AUTOSAR XML (schema 4-2-2)
package /STELLANTIS/EPT/ASWCs
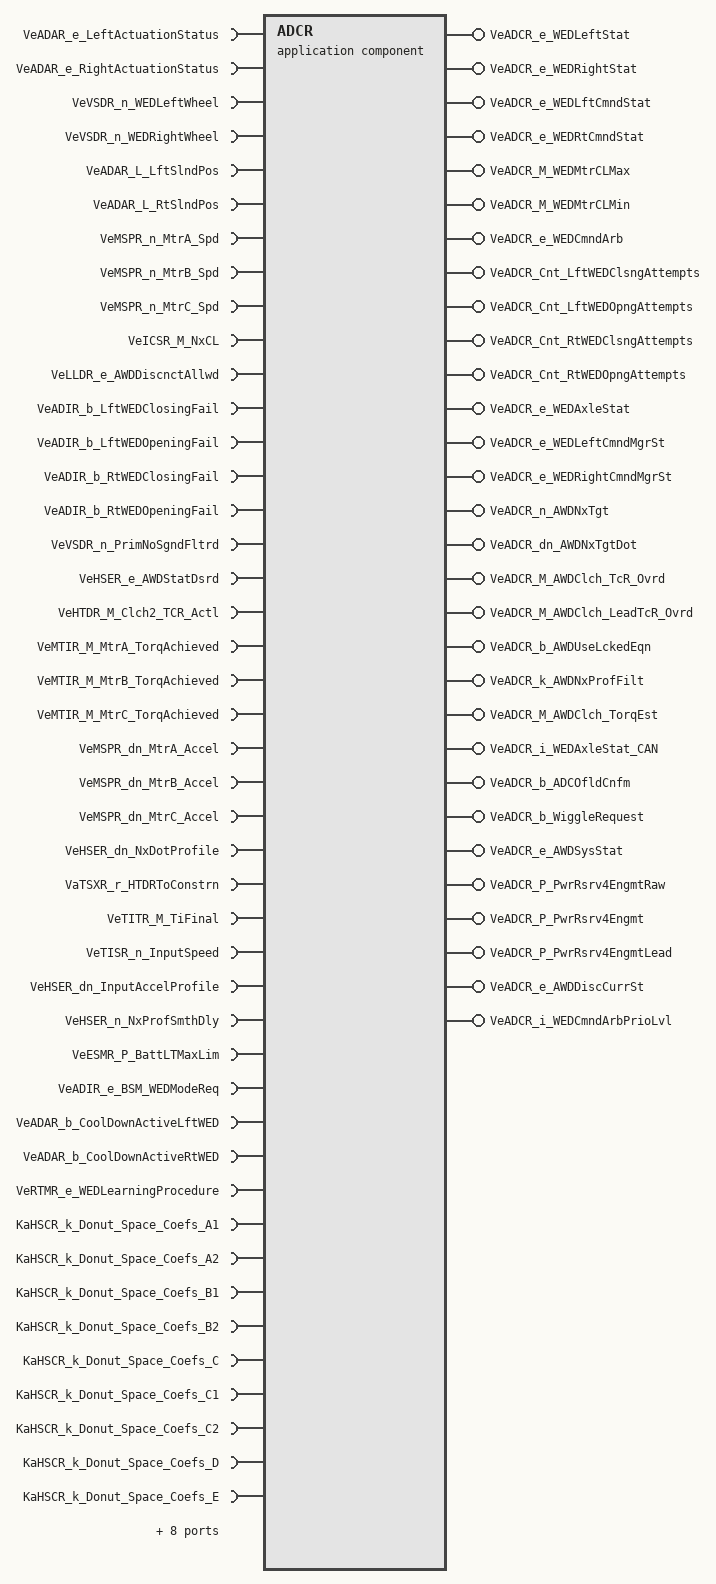
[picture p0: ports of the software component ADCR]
  application sw component type ADCR
    35 x require port:
      VeADAR_e_LeftActuationStatus: variation-point={short-label=vpVeADAR_e_LeftActuationStatus, sw-syscond=1}, nonqueued-receiver-com-spec{data-element=Value, init-value=CeADAR_e_SS_Indeterminate}, required-interface=VeADAR_e_LeftActuationStatus
      VeADAR_e_RightActuationStatus: variation-point={short-label=vpVeADAR_e_RightActuationStatus, sw-syscond=1}, nonqueued-receiver-com-spec{data-element=Value, init-value=CeADAR_e_SS_Indeterminate}, required-interface=VeADAR_e_RightActuationStatus
      VeVSDR_n_WEDLeftWheel: variation-point={short-label=vpVeVSDR_n_WEDLeftWheel, sw-syscond=1}, nonqueued-receiver-com-spec{data-element=Value, init-value=0}, required-interface=VeVSDR_n_WEDLeftWheel
      VeVSDR_n_WEDRightWheel: variation-point={short-label=vpVeVSDR_n_WEDRightWheel, sw-syscond=1}, nonqueued-receiver-com-spec{data-element=Value, init-value=0}, required-interface=VeVSDR_n_WEDRightWheel
      VeADAR_L_LftSlndPos: variation-point={short-label=vpVeADAR_L_LftSlndPos, sw-syscond=1}, nonqueued-receiver-com-spec{data-element=Value, init-value=0}, required-interface=VeADAR_L_LftSlndPos
      VeADAR_L_RtSlndPos: variation-point={short-label=vpVeADAR_L_RtSlndPos, sw-syscond=1}, nonqueued-receiver-com-spec{data-element=Value, init-value=0}, required-interface=VeADAR_L_RtSlndPos
      VeMSPR_n_MtrA_Spd: variation-point={short-label=vpVeMSPR_n_MtrA_Spd, sw-syscond=1}, nonqueued-receiver-com-spec{data-element=Value, init-value=0}, required-interface=VeMSPR_n_MtrA_Spd
      VeMSPR_n_MtrB_Spd: variation-point={short-label=vpVeMSPR_n_MtrB_Spd, sw-syscond=1}, nonqueued-receiver-com-spec{data-element=Value, init-value=0}, required-interface=VeMSPR_n_MtrB_Spd
      VeMSPR_n_MtrC_Spd: variation-point={short-label=vpVeMSPR_n_MtrC_Spd, sw-syscond=1}, nonqueued-receiver-com-spec{data-element=Value, init-value=0}, required-interface=VeMSPR_n_MtrC_Spd
      VeICSR_M_NxCL: variation-point={short-label=vpVeICSR_M_NxCL, sw-syscond=1}, nonqueued-receiver-com-spec{data-element=Value, init-value=0}, required-interface=VeICSR_M_NxCL
      VeLLDR_e_AWDDiscnctAllwd: variation-point={short-label=vpVeLLDR_e_AWDDiscnctAllwd, sw-syscond=1}, nonqueued-receiver-com-spec{data-element=Value, init-value=0}, required-interface=VeLLDR_e_AWDDiscnctAllwd
      VeADIR_b_LftWEDClosingFail: variation-point={short-label=vpVeADIR_b_LftWEDClosingFail, sw-syscond=1}, nonqueued-receiver-com-spec{data-element=Value, init-value=0}, required-interface=VeADIR_b_LftWEDClosingFail
      VeADIR_b_LftWEDOpeningFail: variation-point={short-label=vpVeADIR_b_LftWEDOpeningFail, sw-syscond=1}, nonqueued-receiver-com-spec{data-element=Value, init-value=0}, required-interface=VeADIR_b_LftWEDOpeningFail
      VeADIR_b_RtWEDClosingFail: variation-point={short-label=vpVeADIR_b_RtWEDClosingFail, sw-syscond=1}, nonqueued-receiver-com-spec{data-element=Value, init-value=0}, required-interface=VeADIR_b_RtWEDClosingFail
      VeADIR_b_RtWEDOpeningFail: variation-point={short-label=vpVeADIR_b_RtWEDOpeningFail, sw-syscond=1}, nonqueued-receiver-com-spec{data-element=Value, init-value=0}, required-interface=VeADIR_b_RtWEDOpeningFail
      VeVSDR_n_PrimNoSgndFltrd: variation-point={short-label=vpVeVSDR_n_PrimNoSgndFltrd, sw-syscond=1}, nonqueued-receiver-com-spec{data-element=Value, init-value=0}, required-interface=VeVSDR_n_PrimNoSgndFltrd
      VeHSER_e_AWDStatDsrd: variation-point={short-label=vpVeHSER_e_AWDStatDsrd, sw-syscond=1}, nonqueued-receiver-com-spec{data-element=Value, init-value=CeADCR_e_Init}, required-interface=VeHSER_e_AWDStatDsrd
      VeHTDR_M_Clch2_TCR_Actl: variation-point={short-label=vpVeHTDR_M_Clch2_TCR_Actl, sw-syscond=1}, nonqueued-receiver-com-spec{data-element=Value, init-value=0}, required-interface=VeHTDR_M_Clch2_TCR_Actl
      VeMTIR_M_MtrA_TorqAchieved: variation-point={short-label=vpVeMTIR_M_MtrA_TorqAchieved, sw-syscond=1}, nonqueued-receiver-com-spec{data-element=Value, init-value=0}, required-interface=VeMTIR_M_MtrA_TorqAchieved
      VeMTIR_M_MtrB_TorqAchieved: variation-point={short-label=vpVeMTIR_M_MtrB_TorqAchieved, sw-syscond=1}, nonqueued-receiver-com-spec{data-element=Value, init-value=0}, required-interface=VeMTIR_M_MtrB_TorqAchieved
      VeMTIR_M_MtrC_TorqAchieved: variation-point={short-label=vpVeMTIR_M_MtrC_TorqAchieved, sw-syscond=1}, nonqueued-receiver-com-spec{data-element=Value, init-value=0}, required-interface=VeMTIR_M_MtrC_TorqAchieved
      VeMSPR_dn_MtrA_Accel: variation-point={short-label=vpVeMSPR_dn_MtrA_Accel, sw-syscond=1}, nonqueued-receiver-com-spec{data-element=Value, init-value=0}, required-interface=VeMSPR_dn_MtrA_Accel
      VeMSPR_dn_MtrB_Accel: variation-point={short-label=vpVeMSPR_dn_MtrB_Accel, sw-syscond=1}, nonqueued-receiver-com-spec{data-element=Value, init-value=0}, required-interface=VeMSPR_dn_MtrB_Accel
      VeMSPR_dn_MtrC_Accel: variation-point={short-label=vpVeMSPR_dn_MtrC_Accel, sw-syscond=1}, nonqueued-receiver-com-spec{data-element=Value, init-value=0}, required-interface=VeMSPR_dn_MtrC_Accel
      VeHSER_dn_NxDotProfile: variation-point={short-label=vpVeHSER_dn_NxDotProfile, sw-syscond=1}, nonqueued-receiver-com-spec{data-element=Value, init-value=0}, required-interface=VeHSER_dn_NxDotProfile
      VaTSXR_r_HTDRToConstrn: variation-point={short-label=vpVaTSXR_r_HTDRToConstrn, sw-syscond=1}, nonqueued-receiver-com-spec{data-element=Value, init-value=114 x 0}, required-interface=VaTSXR_r_HTDRToConstrn
      VeTITR_M_TiFinal: variation-point={short-label=vpVeTITR_M_TiFinal, sw-syscond=1}, nonqueued-receiver-com-spec{data-element=Value, init-value=0}, required-interface=VeTITR_M_TiFinal
      VeTISR_n_InputSpeed: variation-point={short-label=vpVeTISR_n_InputSpeed, sw-syscond=1}, nonqueued-receiver-com-spec{data-element=Value, init-value=0}, required-interface=VeTISR_n_InputSpeed
      VeHSER_dn_InputAccelProfile: variation-point={short-label=vpVeHSER_dn_InputAccelProfile, sw-syscond=1}, nonqueued-receiver-com-spec{data-element=Value, init-value=0}, required-interface=VeHSER_dn_InputAccelProfile
      VeHSER_n_NxProfSmthDly: variation-point={short-label=vpVeHSER_n_NxProfSmthDly, sw-syscond=1}, nonqueued-receiver-com-spec{data-element=Value, init-value=0}, required-interface=VeHSER_n_NxProfSmthDly
      VeESMR_P_BattLTMaxLim: variation-point={short-label=vpVeESMR_P_BattLTMaxLim, sw-syscond=1}, nonqueued-receiver-com-spec{data-element=Value, init-value=0}, required-interface=VeESMR_P_BattLTMaxLim
      VeADIR_e_BSM_WEDModeReq: variation-point={short-label=vpVeADIR_e_BSM_WEDModeReq, sw-syscond=1}, nonqueued-receiver-com-spec{data-element=Value, init-value=CeADCR_e_ReqOpt}, required-interface=VeADIR_e_BSM_WEDModeReq
      VeADAR_b_CoolDownActiveLftWED: variation-point={short-label=vpVeADAR_b_CoolDownActiveLftWED, sw-syscond=1}, nonqueued-receiver-com-spec{data-element=Value, init-value=0}, required-interface=VeADAR_b_CoolDownActiveLftWED
      VeADAR_b_CoolDownActiveRtWED: variation-point={short-label=vpVeADAR_b_CoolDownActiveRtWED, sw-syscond=1}, nonqueued-receiver-com-spec{data-element=Value, init-value=0}, required-interface=VeADAR_b_CoolDownActiveRtWED
      VeRTMR_e_WEDLearningProcedure: variation-point={short-label=vpVeRTMR_e_WEDLearningProcedure, sw-syscond=1}, nonqueued-receiver-com-spec{data-element=Value, init-value=CeRTMR_e_WED_Not_Active}, required-interface=VeRTMR_e_WEDLearningProcedure
    30 x provide port:
      VeADCR_e_WEDLeftStat: nonqueued-sender-com-spec{data-element=Value, init-value=CeADCR_e_Init}, provided-interface=VeADCR_e_WEDLeftStat
      VeADCR_e_WEDRightStat: nonqueued-sender-com-spec{data-element=Value, init-value=CeADCR_e_Init}, provided-interface=VeADCR_e_WEDRightStat
      VeADCR_e_WEDLftCmndStat: nonqueued-sender-com-spec{data-element=Value, init-value=CeADCR_e_NoCmnd}, provided-interface=VeADCR_e_WEDLftCmndStat
      VeADCR_e_WEDRtCmndStat: nonqueued-sender-com-spec{data-element=Value, init-value=CeADCR_e_NoCmnd}, provided-interface=VeADCR_e_WEDRtCmndStat
      VeADCR_M_WEDMtrCLMax: nonqueued-sender-com-spec{data-element=Value, init-value=0}, provided-interface=VeADCR_M_WEDMtrCLMax
      VeADCR_M_WEDMtrCLMin: nonqueued-sender-com-spec{data-element=Value, init-value=0}, provided-interface=VeADCR_M_WEDMtrCLMin
      VeADCR_e_WEDCmndArb: nonqueued-sender-com-spec{data-element=Value, init-value=CeADCR_e_ReqOpt}, provided-interface=VeADCR_e_WEDCmndArb
      VeADCR_Cnt_LftWEDClsngAttempts: nonqueued-sender-com-spec{data-element=Value, init-value=0}, provided-interface=VeADCR_Cnt_LftWEDClsngAttempts
      VeADCR_Cnt_LftWEDOpngAttempts: nonqueued-sender-com-spec{data-element=Value, init-value=0}, provided-interface=VeADCR_Cnt_LftWEDOpngAttempts
      VeADCR_Cnt_RtWEDClsngAttempts: nonqueued-sender-com-spec{data-element=Value, init-value=0}, provided-interface=VeADCR_Cnt_RtWEDClsngAttempts
      VeADCR_Cnt_RtWEDOpngAttempts: nonqueued-sender-com-spec{data-element=Value, init-value=0}, provided-interface=VeADCR_Cnt_RtWEDOpngAttempts
      VeADCR_e_WEDAxleStat: nonqueued-sender-com-spec{data-element=Value, init-value=CeADCR_e_Init}, provided-interface=VeADCR_e_WEDAxleStat
      VeADCR_e_WEDLeftCmndMgrSt: nonqueued-sender-com-spec{data-element=Value, init-value=CeADCR_e_WEDCmndInit}, provided-interface=VeADCR_e_WEDLeftCmndMgrSt
      VeADCR_e_WEDRightCmndMgrSt: nonqueued-sender-com-spec{data-element=Value, init-value=CeADCR_e_WEDCmndInit}, provided-interface=VeADCR_e_WEDRightCmndMgrSt
      VeADCR_n_AWDNxTgt: nonqueued-sender-com-spec{data-element=Value, init-value=0}, provided-interface=VeADCR_n_AWDNxTgt
      VeADCR_dn_AWDNxTgtDot: nonqueued-sender-com-spec{data-element=Value, init-value=0}, provided-interface=VeADCR_dn_AWDNxTgtDot
      VeADCR_M_AWDClch_TcR_Ovrd: nonqueued-sender-com-spec{data-element=Value, init-value=0}, provided-interface=VeADCR_M_AWDClch_TcR_Ovrd
      VeADCR_M_AWDClch_LeadTcR_Ovrd: nonqueued-sender-com-spec{data-element=Value, init-value=0}, provided-interface=VeADCR_M_AWDClch_LeadTcR_Ovrd
      VeADCR_b_AWDUseLckedEqn: nonqueued-sender-com-spec{data-element=Value, init-value=0}, provided-interface=VeADCR_b_AWDUseLckedEqn
      VeADCR_k_AWDNxProfFilt: nonqueued-sender-com-spec{data-element=Value, init-value=0}, provided-interface=VeADCR_k_AWDNxProfFilt
      VeADCR_M_AWDClch_TorqEst: nonqueued-sender-com-spec{data-element=Value, init-value=0}, provided-interface=VeADCR_M_AWDClch_TorqEst
      VeADCR_i_WEDAxleStat_CAN: nonqueued-sender-com-spec{data-element=Value, init-value=0}, provided-interface=VeADCR_i_WEDAxleStat_CAN
      VeADCR_b_ADCOfldCnfm: nonqueued-sender-com-spec{data-element=Value, init-value=0}, provided-interface=VeADCR_b_ADCOfldCnfm
      VeADCR_b_WiggleRequest: nonqueued-sender-com-spec{data-element=Value, init-value=0}, provided-interface=VeADCR_b_WiggleRequest
      VeADCR_e_AWDSysStat: nonqueued-sender-com-spec{data-element=Value, init-value=CeADCR_e_TwoWheelDrive}, provided-interface=VeADCR_e_AWDSysStat
      VeADCR_P_PwrRsrv4EngmtRaw: nonqueued-sender-com-spec{data-element=Value, init-value=0}, provided-interface=VeADCR_P_PwrRsrv4EngmtRaw
      VeADCR_P_PwrRsrv4Engmt: nonqueued-sender-com-spec{data-element=Value, init-value=0}, provided-interface=VeADCR_P_PwrRsrv4Engmt
      VeADCR_P_PwrRsrv4EngmtLead: nonqueued-sender-com-spec{data-element=Value, init-value=0}, provided-interface=VeADCR_P_PwrRsrv4EngmtLead
      VeADCR_e_AWDDiscCurrSt: nonqueued-sender-com-spec{data-element=Value, init-value=CeADCR_e_AWDInit}, provided-interface=VeADCR_e_AWDDiscCurrSt
      VeADCR_i_WEDCmndArbPrioLvl: nonqueued-sender-com-spec{data-element=Value, init-value=0}, provided-interface=VeADCR_i_WEDCmndArbPrioLvl
    17 x require port:
      KaHSCR_k_Donut_Space_Coefs_A1: parameter-require-com-spec{init-value=KaHSCR_k_Donut_Space_Coefs_A1_KaHSCR_k_Donut_Space_Coefs_A1:[KaHSCR_k_Donut_Space_Coefs_A1_KaHSCR_k_Donut_Space_Coefs_A1_rt_Array_Float_34_1:0.0258900001645088, KaHSCR_k_Donut_Space_Coefs_A1_KaHSCR_k_Donut_Space_Coefs_A1_rt_Array_Float_34_2:0.0258900001645088, KaHSCR_k_Donut_Space_Coefs_A1_KaHSCR_k_Donut_Space_Coefs_A1_rt_Array_Float_34_3:0.0351000018417835, KaHSCR_k_Donut_Space_Coefs_A1_KaHSCR_k_Donut_Space_Coefs_A1_rt_Array_Float_34_4:0.0372599996626377, KaHSCR_k_Donut_Space_Coefs_A1_KaHSCR_k_Donut_Space_Coefs_A1_rt_Array_Float_34_5:0.0378299988806248, KaHSCR_k_Donut_Space_Coefs_A1_KaHSCR_k_Donut_Space_Coefs_A1_rt_Array_Float_34_6:0.0382400006055832, KaHSCR_k_Donut_Space_Coefs_A1_KaHSCR_k_Donut_Space_Coefs_A1_rt_Array_Float_34_7:0.0386399887502193, KaHSCR_k_Donut_Space_Coefs_A1_KaHSCR_k_Donut_Space_Coefs_A1_rt_Array_Float_34_8:0.0405225306749344, KaHSCR_k_Donut_Space_Coefs_A1_KaHSCR_k_Donut_Space_Coefs_A1_rt_Array_Float_34_9:0.0411508604884148, KaHSCR_k_Donut_Space_Coefs_A1_KaHSCR_k_Donut_Space_Coefs_A1_rt_Array_Float_34_10:0.0418944396078587, KaHSCR_k_Donut_Space_Coefs_A1_KaHSCR_k_Donut_Space_Coefs_A1_rt_Array_Float_34_11:0.0425894781947136, KaHSCR_k_Donut_Space_Coefs_A1_KaHSCR_k_Donut_Space_Coefs_A1_rt_Array_Float_34_12:0.0431920886039734, KaHSCR_k_Donut_Space_Coefs_A1_KaHSCR_k_Donut_Space_Coefs_A1_rt_Array_Float_34_13:0.0436835289001465, KaHSCR_k_Donut_Space_Coefs_A1_KaHSCR_k_Donut_Space_Coefs_A1_rt_Array_Float_34_14:0.0443845391273499, KaHSCR_k_Donut_Space_Coefs_A1_KaHSCR_k_Donut_Space_Coefs_A1_rt_Array_Float_34_15:0.0450701601803303, KaHSCR_k_Donut_Space_Coefs_A1_KaHSCR_k_Donut_Space_Coefs_A1_rt_Array_Float_34_16:0.0456303507089615, KaHSCR_k_Donut_Space_Coefs_A1_KaHSCR_k_Donut_Space_Coefs_A1_rt_Array_Float_34_17:0.0466340184211731, KaHSCR_k_Donut_Space_Coefs_A1_KaHSCR_k_Donut_Space_Coefs_A1_rt_Array_Float_34_18:0.0474497117102146, KaHSCR_k_Donut_Space_Coefs_A1_KaHSCR_k_Donut_Space_Coefs_A1_rt_Array_Float_34_19:0.0479614101350307, KaHSCR_k_Donut_Space_Coefs_A1_KaHSCR_k_Donut_Space_Coefs_A1_rt_Array_Float_34_20:0.0484260395169258, KaHSCR_k_Donut_Space_Coefs_A1_KaHSCR_k_Donut_Space_Coefs_A1_rt_Array_Float_34_21:0.0488490909337997, KaHSCR_k_Donut_Space_Coefs_A1_KaHSCR_k_Donut_Space_Coefs_A1_rt_Array_Float_34_22:0.0494564808905125, KaHSCR_k_Donut_Space_Coefs_A1_KaHSCR_k_Donut_Space_Coefs_A1_rt_Array_Float_34_23:0.050324771553278, KaHSCR_k_Donut_Space_Coefs_A1_KaHSCR_k_Donut_Space_Coefs_A1_rt_Array_Float_34_24:0.0511159785091877, KaHSCR_k_Donut_Space_Coefs_A1_KaHSCR_k_Donut_Space_Coefs_A1_rt_Array_Float_34_25:0.0516291595995426, KaHSCR_k_Donut_Space_Coefs_A1_KaHSCR_k_Donut_Space_Coefs_A1_rt_Array_Float_34_26:0.051756490021944, KaHSCR_k_Donut_Space_Coefs_A1_KaHSCR_k_Donut_Space_Coefs_A1_rt_Array_Float_34_27:0.0519887804985046, KaHSCR_k_Donut_Space_Coefs_A1_KaHSCR_k_Donut_Space_Coefs_A1_rt_Array_Float_34_28:0.0530802011489868, KaHSCR_k_Donut_Space_Coefs_A1_KaHSCR_k_Donut_Space_Coefs_A1_rt_Array_Float_34_29:0.0536961182951927, KaHSCR_k_Donut_Space_Coefs_A1_KaHSCR_k_Donut_Space_Coefs_A1_rt_Array_Float_34_30:0.054239921271801, KaHSCR_k_Donut_Space_Coefs_A1_KaHSCR_k_Donut_Space_Coefs_A1_rt_Array_Float_34_31:0.0550949200987816, KaHSCR_k_Donut_Space_Coefs_A1_KaHSCR_k_Donut_Space_Coefs_A1_rt_Array_Float_34_32:0.0563113614916801, KaHSCR_k_Donut_Space_Coefs_A1_KaHSCR_k_Donut_Space_Coefs_A1_rt_Array_Float_34_33:0.0575419701635838, KaHSCR_k_Donut_Space_Coefs_A1_KaHSCR_k_Donut_Space_Coefs_A1_rt_Array_Float_34_34:0.0587838590145111], parameter=KaHSCR_k_Donut_Space_Coefs_A1}, required-interface=KaHSCR_k_Donut_Space_Coefs_A1
      KaHSCR_k_Donut_Space_Coefs_A2: parameter-require-com-spec{init-value=KaHSCR_k_Donut_Space_Coefs_A2_KaHSCR_k_Donut_Space_Coefs_A2:[KaHSCR_k_Donut_Space_Coefs_A2_KaHSCR_k_Donut_Space_Coefs_A2_rt_Array_Float_34_1:-5.04978709276475E-18, KaHSCR_k_Donut_Space_Coefs_A2_KaHSCR_k_Donut_Space_Coefs_A2_rt_Array_Float_34_2:-5.04978709276475E-18, KaHSCR_k_Donut_Space_Coefs_A2_KaHSCR_k_Donut_Space_Coefs_A2_rt_Array_Float_34_3:0.639999985694885, KaHSCR_k_Donut_Space_Coefs_A2_KaHSCR_k_Donut_Space_Coefs_A2_rt_Array_Float_34_4:1.19000005722046, KaHSCR_k_Donut_Space_Coefs_A2_KaHSCR_k_Donut_Space_Coefs_A2_rt_Array_Float_34_5:1.75999999046326, KaHSCR_k_Donut_Space_Coefs_A2_KaHSCR_k_Donut_Space_Coefs_A2_rt_Array_Float_34_6:2.30999994277954, KaHSCR_k_Donut_Space_Coefs_A2_KaHSCR_k_Donut_Space_Coefs_A2_rt_Array_Float_34_7:2.85999989509583, KaHSCR_k_Donut_Space_Coefs_A2_KaHSCR_k_Donut_Space_Coefs_A2_rt_Array_Float_34_8:3.33561706542969, KaHSCR_k_Donut_Space_Coefs_A2_KaHSCR_k_Donut_Space_Coefs_A2_rt_Array_Float_34_9:3.81586289405823, KaHSCR_k_Donut_Space_Coefs_A2_KaHSCR_k_Donut_Space_Coefs_A2_rt_Array_Float_34_10:4.27816390991211, KaHSCR_k_Donut_Space_Coefs_A2_KaHSCR_k_Donut_Space_Coefs_A2_rt_Array_Float_34_11:4.72691488265991, KaHSCR_k_Donut_Space_Coefs_A2_KaHSCR_k_Donut_Space_Coefs_A2_rt_Array_Float_34_12:5.16561794281006, KaHSCR_k_Donut_Space_Coefs_A2_KaHSCR_k_Donut_Space_Coefs_A2_rt_Array_Float_34_13:5.61427307128906, KaHSCR_k_Donut_Space_Coefs_A2_KaHSCR_k_Donut_Space_Coefs_A2_rt_Array_Float_34_14:6.01499605178833, KaHSCR_k_Donut_Space_Coefs_A2_KaHSCR_k_Donut_Space_Coefs_A2_rt_Array_Float_34_15:6.42061996459961, KaHSCR_k_Donut_Space_Coefs_A2_KaHSCR_k_Donut_Space_Coefs_A2_rt_Array_Float_34_16:6.81864976882935, KaHSCR_k_Donut_Space_Coefs_A2_KaHSCR_k_Donut_Space_Coefs_A2_rt_Array_Float_34_17:7.15260887145996, KaHSCR_k_Donut_Space_Coefs_A2_KaHSCR_k_Donut_Space_Coefs_A2_rt_Array_Float_34_18:7.50815296173096, KaHSCR_k_Donut_Space_Coefs_A2_KaHSCR_k_Donut_Space_Coefs_A2_rt_Array_Float_34_19:7.88588094711304, KaHSCR_k_Donut_Space_Coefs_A2_KaHSCR_k_Donut_Space_Coefs_A2_rt_Array_Float_34_20:8.26707172393799, KaHSCR_k_Donut_Space_Coefs_A2_KaHSCR_k_Donut_Space_Coefs_A2_rt_Array_Float_34_21:8.64353656768799, KaHSCR_k_Donut_Space_Coefs_A2_KaHSCR_k_Donut_Space_Coefs_A2_rt_Array_Float_34_22:8.99045372009277, KaHSCR_k_Donut_Space_Coefs_A2_KaHSCR_k_Donut_Space_Coefs_A2_rt_Array_Float_34_23:9.27973079681396, KaHSCR_k_Donut_Space_Coefs_A2_KaHSCR_k_Donut_Space_Coefs_A2_rt_Array_Float_34_24:9.56464672088623, KaHSCR_k_Donut_Space_Coefs_A2_KaHSCR_k_Donut_Space_Coefs_A2_rt_Array_Float_34_25:9.88457489013672, KaHSCR_k_Donut_Space_Coefs_A2_KaHSCR_k_Donut_Space_Coefs_A2_rt_Array_Float_34_26:10.2705402374268, KaHSCR_k_Donut_Space_Coefs_A2_KaHSCR_k_Donut_Space_Coefs_A2_rt_Array_Float_34_27:10.658860206604, KaHSCR_k_Donut_Space_Coefs_A2_KaHSCR_k_Donut_Space_Coefs_A2_rt_Array_Float_34_28:10.8600997924805, KaHSCR_k_Donut_Space_Coefs_A2_KaHSCR_k_Donut_Space_Coefs_A2_rt_Array_Float_34_29:11.1487503051758, KaHSCR_k_Donut_Space_Coefs_A2_KaHSCR_k_Donut_Space_Coefs_A2_rt_Array_Float_34_30:11.4441699981689, KaHSCR_k_Donut_Space_Coefs_A2_KaHSCR_k_Donut_Space_Coefs_A2_rt_Array_Float_34_31:11.6732902526855, KaHSCR_k_Donut_Space_Coefs_A2_KaHSCR_k_Donut_Space_Coefs_A2_rt_Array_Float_34_32:11.8130502700806, KaHSCR_k_Donut_Space_Coefs_A2_KaHSCR_k_Donut_Space_Coefs_A2_rt_Array_Float_34_33:11.9453201293945, KaHSCR_k_Donut_Space_Coefs_A2_KaHSCR_k_Donut_Space_Coefs_A2_rt_Array_Float_34_34:12.0616703033447], parameter=KaHSCR_k_Donut_Space_Coefs_A2}, required-interface=KaHSCR_k_Donut_Space_Coefs_A2
      KaHSCR_k_Donut_Space_Coefs_B1: parameter-require-com-spec{init-value=KaHSCR_k_Donut_Space_Coefs_B1_KaHSCR_k_Donut_Space_Coefs_B1:[KaHSCR_k_Donut_Space_Coefs_B1_KaHSCR_k_Donut_Space_Coefs_B1_rt_Array_Float_34_1:0.0258900001645088, KaHSCR_k_Donut_Space_Coefs_B1_KaHSCR_k_Donut_Space_Coefs_B1_rt_Array_Float_34_2:0.0258900001645088, KaHSCR_k_Donut_Space_Coefs_B1_KaHSCR_k_Donut_Space_Coefs_B1_rt_Array_Float_34_3:0.0351000018417835, KaHSCR_k_Donut_Space_Coefs_B1_KaHSCR_k_Donut_Space_Coefs_B1_rt_Array_Float_34_4:0.0372599996626377, KaHSCR_k_Donut_Space_Coefs_B1_KaHSCR_k_Donut_Space_Coefs_B1_rt_Array_Float_34_5:0.0378299988806248, KaHSCR_k_Donut_Space_Coefs_B1_KaHSCR_k_Donut_Space_Coefs_B1_rt_Array_Float_34_6:0.0382400006055832, KaHSCR_k_Donut_Space_Coefs_B1_KaHSCR_k_Donut_Space_Coefs_B1_rt_Array_Float_34_7:0.0386399887502193, KaHSCR_k_Donut_Space_Coefs_B1_KaHSCR_k_Donut_Space_Coefs_B1_rt_Array_Float_34_8:0.0405225306749344, KaHSCR_k_Donut_Space_Coefs_B1_KaHSCR_k_Donut_Space_Coefs_B1_rt_Array_Float_34_9:0.0411508604884148, KaHSCR_k_Donut_Space_Coefs_B1_KaHSCR_k_Donut_Space_Coefs_B1_rt_Array_Float_34_10:0.0418944396078587, KaHSCR_k_Donut_Space_Coefs_B1_KaHSCR_k_Donut_Space_Coefs_B1_rt_Array_Float_34_11:0.0425894781947136, KaHSCR_k_Donut_Space_Coefs_B1_KaHSCR_k_Donut_Space_Coefs_B1_rt_Array_Float_34_12:0.0431920886039734, KaHSCR_k_Donut_Space_Coefs_B1_KaHSCR_k_Donut_Space_Coefs_B1_rt_Array_Float_34_13:0.0436835289001465, KaHSCR_k_Donut_Space_Coefs_B1_KaHSCR_k_Donut_Space_Coefs_B1_rt_Array_Float_34_14:0.0443845391273499, KaHSCR_k_Donut_Space_Coefs_B1_KaHSCR_k_Donut_Space_Coefs_B1_rt_Array_Float_34_15:0.0450701601803303, KaHSCR_k_Donut_Space_Coefs_B1_KaHSCR_k_Donut_Space_Coefs_B1_rt_Array_Float_34_16:0.0456303507089615, KaHSCR_k_Donut_Space_Coefs_B1_KaHSCR_k_Donut_Space_Coefs_B1_rt_Array_Float_34_17:0.0466340184211731, KaHSCR_k_Donut_Space_Coefs_B1_KaHSCR_k_Donut_Space_Coefs_B1_rt_Array_Float_34_18:0.0474497117102146, KaHSCR_k_Donut_Space_Coefs_B1_KaHSCR_k_Donut_Space_Coefs_B1_rt_Array_Float_34_19:0.0479614101350307, KaHSCR_k_Donut_Space_Coefs_B1_KaHSCR_k_Donut_Space_Coefs_B1_rt_Array_Float_34_20:0.0484260395169258, KaHSCR_k_Donut_Space_Coefs_B1_KaHSCR_k_Donut_Space_Coefs_B1_rt_Array_Float_34_21:0.0488490909337997, KaHSCR_k_Donut_Space_Coefs_B1_KaHSCR_k_Donut_Space_Coefs_B1_rt_Array_Float_34_22:0.0494564808905125, KaHSCR_k_Donut_Space_Coefs_B1_KaHSCR_k_Donut_Space_Coefs_B1_rt_Array_Float_34_23:0.050324771553278, KaHSCR_k_Donut_Space_Coefs_B1_KaHSCR_k_Donut_Space_Coefs_B1_rt_Array_Float_34_24:0.0511159785091877, KaHSCR_k_Donut_Space_Coefs_B1_KaHSCR_k_Donut_Space_Coefs_B1_rt_Array_Float_34_25:0.0516291595995426, KaHSCR_k_Donut_Space_Coefs_B1_KaHSCR_k_Donut_Space_Coefs_B1_rt_Array_Float_34_26:0.051756490021944, KaHSCR_k_Donut_Space_Coefs_B1_KaHSCR_k_Donut_Space_Coefs_B1_rt_Array_Float_34_27:0.0519887804985046, KaHSCR_k_Donut_Space_Coefs_B1_KaHSCR_k_Donut_Space_Coefs_B1_rt_Array_Float_34_28:0.0530802011489868, KaHSCR_k_Donut_Space_Coefs_B1_KaHSCR_k_Donut_Space_Coefs_B1_rt_Array_Float_34_29:0.0536961182951927, KaHSCR_k_Donut_Space_Coefs_B1_KaHSCR_k_Donut_Space_Coefs_B1_rt_Array_Float_34_30:0.054239921271801, KaHSCR_k_Donut_Space_Coefs_B1_KaHSCR_k_Donut_Space_Coefs_B1_rt_Array_Float_34_31:0.0550949200987816, KaHSCR_k_Donut_Space_Coefs_B1_KaHSCR_k_Donut_Space_Coefs_B1_rt_Array_Float_34_32:0.0563113614916801, KaHSCR_k_Donut_Space_Coefs_B1_KaHSCR_k_Donut_Space_Coefs_B1_rt_Array_Float_34_33:0.0575419701635838, KaHSCR_k_Donut_Space_Coefs_B1_KaHSCR_k_Donut_Space_Coefs_B1_rt_Array_Float_34_34:0.0587838590145111], parameter=KaHSCR_k_Donut_Space_Coefs_B1}, required-interface=KaHSCR_k_Donut_Space_Coefs_B1
      KaHSCR_k_Donut_Space_Coefs_B2: parameter-require-com-spec{init-value=KaHSCR_k_Donut_Space_Coefs_B2_KaHSCR_k_Donut_Space_Coefs_B2:[KaHSCR_k_Donut_Space_Coefs_B2_KaHSCR_k_Donut_Space_Coefs_B2_rt_Array_Float_34_1:-5.04978709276475E-18, KaHSCR_k_Donut_Space_Coefs_B2_KaHSCR_k_Donut_Space_Coefs_B2_rt_Array_Float_34_2:-5.04978709276475E-18, KaHSCR_k_Donut_Space_Coefs_B2_KaHSCR_k_Donut_Space_Coefs_B2_rt_Array_Float_34_3:0.639999985694885, KaHSCR_k_Donut_Space_Coefs_B2_KaHSCR_k_Donut_Space_Coefs_B2_rt_Array_Float_34_4:1.19000005722046, KaHSCR_k_Donut_Space_Coefs_B2_KaHSCR_k_Donut_Space_Coefs_B2_rt_Array_Float_34_5:1.75999999046326, KaHSCR_k_Donut_Space_Coefs_B2_KaHSCR_k_Donut_Space_Coefs_B2_rt_Array_Float_34_6:2.30999994277954, KaHSCR_k_Donut_Space_Coefs_B2_KaHSCR_k_Donut_Space_Coefs_B2_rt_Array_Float_34_7:2.85999989509583, KaHSCR_k_Donut_Space_Coefs_B2_KaHSCR_k_Donut_Space_Coefs_B2_rt_Array_Float_34_8:3.33561706542969, KaHSCR_k_Donut_Space_Coefs_B2_KaHSCR_k_Donut_Space_Coefs_B2_rt_Array_Float_34_9:3.81586289405823, KaHSCR_k_Donut_Space_Coefs_B2_KaHSCR_k_Donut_Space_Coefs_B2_rt_Array_Float_34_10:4.27816390991211, KaHSCR_k_Donut_Space_Coefs_B2_KaHSCR_k_Donut_Space_Coefs_B2_rt_Array_Float_34_11:4.72691488265991, KaHSCR_k_Donut_Space_Coefs_B2_KaHSCR_k_Donut_Space_Coefs_B2_rt_Array_Float_34_12:5.16561794281006, KaHSCR_k_Donut_Space_Coefs_B2_KaHSCR_k_Donut_Space_Coefs_B2_rt_Array_Float_34_13:5.61427307128906, KaHSCR_k_Donut_Space_Coefs_B2_KaHSCR_k_Donut_Space_Coefs_B2_rt_Array_Float_34_14:6.01499605178833, KaHSCR_k_Donut_Space_Coefs_B2_KaHSCR_k_Donut_Space_Coefs_B2_rt_Array_Float_34_15:6.42061996459961, KaHSCR_k_Donut_Space_Coefs_B2_KaHSCR_k_Donut_Space_Coefs_B2_rt_Array_Float_34_16:6.81864976882935, KaHSCR_k_Donut_Space_Coefs_B2_KaHSCR_k_Donut_Space_Coefs_B2_rt_Array_Float_34_17:7.15260887145996, KaHSCR_k_Donut_Space_Coefs_B2_KaHSCR_k_Donut_Space_Coefs_B2_rt_Array_Float_34_18:7.50815296173096, KaHSCR_k_Donut_Space_Coefs_B2_KaHSCR_k_Donut_Space_Coefs_B2_rt_Array_Float_34_19:7.88588094711304, KaHSCR_k_Donut_Space_Coefs_B2_KaHSCR_k_Donut_Space_Coefs_B2_rt_Array_Float_34_20:8.26707172393799, KaHSCR_k_Donut_Space_Coefs_B2_KaHSCR_k_Donut_Space_Coefs_B2_rt_Array_Float_34_21:8.64353656768799, KaHSCR_k_Donut_Space_Coefs_B2_KaHSCR_k_Donut_Space_Coefs_B2_rt_Array_Float_34_22:8.99045372009277, KaHSCR_k_Donut_Space_Coefs_B2_KaHSCR_k_Donut_Space_Coefs_B2_rt_Array_Float_34_23:9.27973079681396, KaHSCR_k_Donut_Space_Coefs_B2_KaHSCR_k_Donut_Space_Coefs_B2_rt_Array_Float_34_24:9.56464672088623, KaHSCR_k_Donut_Space_Coefs_B2_KaHSCR_k_Donut_Space_Coefs_B2_rt_Array_Float_34_25:9.88457489013672, KaHSCR_k_Donut_Space_Coefs_B2_KaHSCR_k_Donut_Space_Coefs_B2_rt_Array_Float_34_26:10.2705402374268, KaHSCR_k_Donut_Space_Coefs_B2_KaHSCR_k_Donut_Space_Coefs_B2_rt_Array_Float_34_27:10.658860206604, KaHSCR_k_Donut_Space_Coefs_B2_KaHSCR_k_Donut_Space_Coefs_B2_rt_Array_Float_34_28:10.8600997924805, KaHSCR_k_Donut_Space_Coefs_B2_KaHSCR_k_Donut_Space_Coefs_B2_rt_Array_Float_34_29:11.1487503051758, KaHSCR_k_Donut_Space_Coefs_B2_KaHSCR_k_Donut_Space_Coefs_B2_rt_Array_Float_34_30:11.4441699981689, KaHSCR_k_Donut_Space_Coefs_B2_KaHSCR_k_Donut_Space_Coefs_B2_rt_Array_Float_34_31:11.6732902526855, KaHSCR_k_Donut_Space_Coefs_B2_KaHSCR_k_Donut_Space_Coefs_B2_rt_Array_Float_34_32:11.8130502700806, KaHSCR_k_Donut_Space_Coefs_B2_KaHSCR_k_Donut_Space_Coefs_B2_rt_Array_Float_34_33:11.9453201293945, KaHSCR_k_Donut_Space_Coefs_B2_KaHSCR_k_Donut_Space_Coefs_B2_rt_Array_Float_34_34:12.0616703033447], parameter=KaHSCR_k_Donut_Space_Coefs_B2}, required-interface=KaHSCR_k_Donut_Space_Coefs_B2
      KaHSCR_k_Donut_Space_Coefs_C: parameter-require-com-spec{init-value=KaHSCR_k_Donut_Space_Coefs_C_KaHSCR_k_Donut_Space_Coefs_C:[KaHSCR_k_Donut_Space_Coefs_C_KaHSCR_k_Donut_Space_Coefs_C_rt_Array_Float_34_1:0.103308998048306, KaHSCR_k_Donut_Space_Coefs_C_KaHSCR_k_Donut_Space_Coefs_C_rt_Array_Float_34_2:0.103308998048306, KaHSCR_k_Donut_Space_Coefs_C_KaHSCR_k_Donut_Space_Coefs_C_rt_Array_Float_34_3:-0.211907997727394, KaHSCR_k_Donut_Space_Coefs_C_KaHSCR_k_Donut_Space_Coefs_C_rt_Array_Float_34_4:-1.20062398910522, KaHSCR_k_Donut_Space_Coefs_C_KaHSCR_k_Donut_Space_Coefs_C_rt_Array_Float_34_5:-2.85137605667114, KaHSCR_k_Donut_Space_Coefs_C_KaHSCR_k_Donut_Space_Coefs_C_rt_Array_Float_34_6:-5.10159778594971, KaHSCR_k_Donut_Space_Coefs_C_KaHSCR_k_Donut_Space_Coefs_C_rt_Array_Float_34_7:-7.90723323822021, KaHSCR_k_Donut_Space_Coefs_C_KaHSCR_k_Donut_Space_Coefs_C_rt_Array_Float_34_8:-10.5811996459961, KaHSCR_k_Donut_Space_Coefs_C_KaHSCR_k_Donut_Space_Coefs_C_rt_Array_Float_34_9:-14.0026197433472, KaHSCR_k_Donut_Space_Coefs_C_KaHSCR_k_Donut_Space_Coefs_C_rt_Array_Float_34_10:-17.6751308441162, KaHSCR_k_Donut_Space_Coefs_C_KaHSCR_k_Donut_Space_Coefs_C_rt_Array_Float_34_11:-21.6737899780273, KaHSCR_k_Donut_Space_Coefs_C_KaHSCR_k_Donut_Space_Coefs_C_rt_Array_Float_34_12:-26.0248203277588, KaHSCR_k_Donut_Space_Coefs_C_KaHSCR_k_Donut_Space_Coefs_C_rt_Array_Float_34_13:-30.7496299743652, KaHSCR_k_Donut_Space_Coefs_C_KaHSCR_k_Donut_Space_Coefs_C_rt_Array_Float_34_14:-35.452018737793, KaHSCR_k_Donut_Space_Coefs_C_KaHSCR_k_Donut_Space_Coefs_C_rt_Array_Float_34_15:-40.3361701965332, KaHSCR_k_Donut_Space_Coefs_C_KaHSCR_k_Donut_Space_Coefs_C_rt_Array_Float_34_16:-45.6424903869629, KaHSCR_k_Donut_Space_Coefs_C_KaHSCR_k_Donut_Space_Coefs_C_rt_Array_Float_34_17:-50.2698593139648, KaHSCR_k_Donut_Space_Coefs_C_KaHSCR_k_Donut_Space_Coefs_C_rt_Array_Float_34_18:-55.375659942627, KaHSCR_k_Donut_Space_Coefs_C_KaHSCR_k_Donut_Space_Coefs_C_rt_Array_Float_34_19:-61.2313995361328, KaHSCR_k_Donut_Space_Coefs_C_KaHSCR_k_Donut_Space_Coefs_C_rt_Array_Float_34_20:-67.2626876831055, KaHSCR_k_Donut_Space_Coefs_C_KaHSCR_k_Donut_Space_Coefs_C_rt_Array_Float_34_21:-73.5646362304688, KaHSCR_k_Donut_Space_Coefs_C_KaHSCR_k_Donut_Space_Coefs_C_rt_Array_Float_34_22:-79.621467590332, KaHSCR_k_Donut_Space_Coefs_C_KaHSCR_k_Donut_Space_Coefs_C_rt_Array_Float_34_23:-84.9908294677734, KaHSCR_k_Donut_Space_Coefs_C_KaHSCR_k_Donut_Space_Coefs_C_rt_Array_Float_34_24:-90.269172668457, KaHSCR_k_Donut_Space_Coefs_C_KaHSCR_k_Donut_Space_Coefs_C_rt_Array_Float_34_25:-96.3239364624023, KaHSCR_k_Donut_Space_Coefs_C_KaHSCR_k_Donut_Space_Coefs_C_rt_Array_Float_34_26:-104.145500183105, KaHSCR_k_Donut_Space_Coefs_C_KaHSCR_k_Donut_Space_Coefs_C_rt_Array_Float_34_27:-112.130699157715, KaHSCR_k_Donut_Space_Coefs_C_KaHSCR_k_Donut_Space_Coefs_C_rt_Array_Float_34_28:-116.38639831543, KaHSCR_k_Donut_Space_Coefs_C_KaHSCR_k_Donut_Space_Coefs_C_rt_Array_Float_34_29:-122.710998535156, KaHSCR_k_Donut_Space_Coefs_C_KaHSCR_k_Donut_Space_Coefs_C_rt_Array_Float_34_30:-129.441192626953, KaHSCR_k_Donut_Space_Coefs_C_KaHSCR_k_Donut_Space_Coefs_C_rt_Array_Float_34_31:-134.5126953125, KaHSCR_k_Donut_Space_Coefs_C_KaHSCR_k_Donut_Space_Coefs_C_rt_Array_Float_34_32:-137.768402099609, KaHSCR_k_Donut_Space_Coefs_C_KaHSCR_k_Donut_Space_Coefs_C_rt_Array_Float_34_33:-140.760498046875, KaHSCR_k_Donut_Space_Coefs_C_KaHSCR_k_Donut_Space_Coefs_C_rt_Array_Float_34_34:-143.608093261719], parameter=KaHSCR_k_Donut_Space_Coefs_C}, required-interface=KaHSCR_k_Donut_Space_Coefs_C
      KaHSCR_k_Donut_Space_Coefs_C1: parameter-require-com-spec{init-value=KaHSCR_k_Donut_Space_Coefs_C1_KaHSCR_k_Donut_Space_Coefs_C1:[KaHSCR_k_Donut_Space_Coefs_C1_KaHSCR_k_Donut_Space_Coefs_C1_rt_Array_Float_34_1:0.0258900001645088, KaHSCR_k_Donut_Space_Coefs_C1_KaHSCR_k_Donut_Space_Coefs_C1_rt_Array_Float_34_2:0.0258900001645088, KaHSCR_k_Donut_Space_Coefs_C1_KaHSCR_k_Donut_Space_Coefs_C1_rt_Array_Float_34_3:0.0351000018417835, KaHSCR_k_Donut_Space_Coefs_C1_KaHSCR_k_Donut_Space_Coefs_C1_rt_Array_Float_34_4:0.0372599996626377, KaHSCR_k_Donut_Space_Coefs_C1_KaHSCR_k_Donut_Space_Coefs_C1_rt_Array_Float_34_5:0.0378299988806248, KaHSCR_k_Donut_Space_Coefs_C1_KaHSCR_k_Donut_Space_Coefs_C1_rt_Array_Float_34_6:0.0382400006055832, KaHSCR_k_Donut_Space_Coefs_C1_KaHSCR_k_Donut_Space_Coefs_C1_rt_Array_Float_34_7:0.0386399887502193, KaHSCR_k_Donut_Space_Coefs_C1_KaHSCR_k_Donut_Space_Coefs_C1_rt_Array_Float_34_8:0.0405225306749344, KaHSCR_k_Donut_Space_Coefs_C1_KaHSCR_k_Donut_Space_Coefs_C1_rt_Array_Float_34_9:0.0411508604884148, KaHSCR_k_Donut_Space_Coefs_C1_KaHSCR_k_Donut_Space_Coefs_C1_rt_Array_Float_34_10:0.0418944396078587, KaHSCR_k_Donut_Space_Coefs_C1_KaHSCR_k_Donut_Space_Coefs_C1_rt_Array_Float_34_11:0.0425894781947136, KaHSCR_k_Donut_Space_Coefs_C1_KaHSCR_k_Donut_Space_Coefs_C1_rt_Array_Float_34_12:0.0431920886039734, KaHSCR_k_Donut_Space_Coefs_C1_KaHSCR_k_Donut_Space_Coefs_C1_rt_Array_Float_34_13:0.0436835289001465, KaHSCR_k_Donut_Space_Coefs_C1_KaHSCR_k_Donut_Space_Coefs_C1_rt_Array_Float_34_14:0.0443845391273499, KaHSCR_k_Donut_Space_Coefs_C1_KaHSCR_k_Donut_Space_Coefs_C1_rt_Array_Float_34_15:0.0450701601803303, KaHSCR_k_Donut_Space_Coefs_C1_KaHSCR_k_Donut_Space_Coefs_C1_rt_Array_Float_34_16:0.0456303507089615, KaHSCR_k_Donut_Space_Coefs_C1_KaHSCR_k_Donut_Space_Coefs_C1_rt_Array_Float_34_17:0.0466340184211731, KaHSCR_k_Donut_Space_Coefs_C1_KaHSCR_k_Donut_Space_Coefs_C1_rt_Array_Float_34_18:0.0474497117102146, KaHSCR_k_Donut_Space_Coefs_C1_KaHSCR_k_Donut_Space_Coefs_C1_rt_Array_Float_34_19:0.0479614101350307, KaHSCR_k_Donut_Space_Coefs_C1_KaHSCR_k_Donut_Space_Coefs_C1_rt_Array_Float_34_20:0.0484260395169258, KaHSCR_k_Donut_Space_Coefs_C1_KaHSCR_k_Donut_Space_Coefs_C1_rt_Array_Float_34_21:0.0488490909337997, KaHSCR_k_Donut_Space_Coefs_C1_KaHSCR_k_Donut_Space_Coefs_C1_rt_Array_Float_34_22:0.0494564808905125, KaHSCR_k_Donut_Space_Coefs_C1_KaHSCR_k_Donut_Space_Coefs_C1_rt_Array_Float_34_23:0.050324771553278, KaHSCR_k_Donut_Space_Coefs_C1_KaHSCR_k_Donut_Space_Coefs_C1_rt_Array_Float_34_24:0.0511159785091877, KaHSCR_k_Donut_Space_Coefs_C1_KaHSCR_k_Donut_Space_Coefs_C1_rt_Array_Float_34_25:0.0516291595995426, KaHSCR_k_Donut_Space_Coefs_C1_KaHSCR_k_Donut_Space_Coefs_C1_rt_Array_Float_34_26:0.051756490021944, KaHSCR_k_Donut_Space_Coefs_C1_KaHSCR_k_Donut_Space_Coefs_C1_rt_Array_Float_34_27:0.0519887804985046, KaHSCR_k_Donut_Space_Coefs_C1_KaHSCR_k_Donut_Space_Coefs_C1_rt_Array_Float_34_28:0.0530802011489868, KaHSCR_k_Donut_Space_Coefs_C1_KaHSCR_k_Donut_Space_Coefs_C1_rt_Array_Float_34_29:0.0536961182951927, KaHSCR_k_Donut_Space_Coefs_C1_KaHSCR_k_Donut_Space_Coefs_C1_rt_Array_Float_34_30:0.054239921271801, KaHSCR_k_Donut_Space_Coefs_C1_KaHSCR_k_Donut_Space_Coefs_C1_rt_Array_Float_34_31:0.0550949200987816, KaHSCR_k_Donut_Space_Coefs_C1_KaHSCR_k_Donut_Space_Coefs_C1_rt_Array_Float_34_32:0.0563113614916801, KaHSCR_k_Donut_Space_Coefs_C1_KaHSCR_k_Donut_Space_Coefs_C1_rt_Array_Float_34_33:0.0575419701635838, KaHSCR_k_Donut_Space_Coefs_C1_KaHSCR_k_Donut_Space_Coefs_C1_rt_Array_Float_34_34:0.0587838590145111], parameter=KaHSCR_k_Donut_Space_Coefs_C1}, required-interface=KaHSCR_k_Donut_Space_Coefs_C1
      KaHSCR_k_Donut_Space_Coefs_C2: parameter-require-com-spec{init-value=KaHSCR_k_Donut_Space_Coefs_C2_KaHSCR_k_Donut_Space_Coefs_C2:[KaHSCR_k_Donut_Space_Coefs_C2_KaHSCR_k_Donut_Space_Coefs_C2_rt_Array_Float_34_1:-5.04978709276475E-18, KaHSCR_k_Donut_Space_Coefs_C2_KaHSCR_k_Donut_Space_Coefs_C2_rt_Array_Float_34_2:-5.04978709276475E-18, KaHSCR_k_Donut_Space_Coefs_C2_KaHSCR_k_Donut_Space_Coefs_C2_rt_Array_Float_34_3:0.639999985694885, KaHSCR_k_Donut_Space_Coefs_C2_KaHSCR_k_Donut_Space_Coefs_C2_rt_Array_Float_34_4:1.19000005722046, KaHSCR_k_Donut_Space_Coefs_C2_KaHSCR_k_Donut_Space_Coefs_C2_rt_Array_Float_34_5:1.75999999046326, KaHSCR_k_Donut_Space_Coefs_C2_KaHSCR_k_Donut_Space_Coefs_C2_rt_Array_Float_34_6:2.30999994277954, KaHSCR_k_Donut_Space_Coefs_C2_KaHSCR_k_Donut_Space_Coefs_C2_rt_Array_Float_34_7:2.85999989509583, KaHSCR_k_Donut_Space_Coefs_C2_KaHSCR_k_Donut_Space_Coefs_C2_rt_Array_Float_34_8:3.33561706542969, KaHSCR_k_Donut_Space_Coefs_C2_KaHSCR_k_Donut_Space_Coefs_C2_rt_Array_Float_34_9:3.81586289405823, KaHSCR_k_Donut_Space_Coefs_C2_KaHSCR_k_Donut_Space_Coefs_C2_rt_Array_Float_34_10:4.27816390991211, KaHSCR_k_Donut_Space_Coefs_C2_KaHSCR_k_Donut_Space_Coefs_C2_rt_Array_Float_34_11:4.72691488265991, KaHSCR_k_Donut_Space_Coefs_C2_KaHSCR_k_Donut_Space_Coefs_C2_rt_Array_Float_34_12:5.16561794281006, KaHSCR_k_Donut_Space_Coefs_C2_KaHSCR_k_Donut_Space_Coefs_C2_rt_Array_Float_34_13:5.61427307128906, KaHSCR_k_Donut_Space_Coefs_C2_KaHSCR_k_Donut_Space_Coefs_C2_rt_Array_Float_34_14:6.01499605178833, KaHSCR_k_Donut_Space_Coefs_C2_KaHSCR_k_Donut_Space_Coefs_C2_rt_Array_Float_34_15:6.42061996459961, KaHSCR_k_Donut_Space_Coefs_C2_KaHSCR_k_Donut_Space_Coefs_C2_rt_Array_Float_34_16:6.81864976882935, KaHSCR_k_Donut_Space_Coefs_C2_KaHSCR_k_Donut_Space_Coefs_C2_rt_Array_Float_34_17:7.15260887145996, KaHSCR_k_Donut_Space_Coefs_C2_KaHSCR_k_Donut_Space_Coefs_C2_rt_Array_Float_34_18:7.50815296173096, KaHSCR_k_Donut_Space_Coefs_C2_KaHSCR_k_Donut_Space_Coefs_C2_rt_Array_Float_34_19:7.88588094711304, KaHSCR_k_Donut_Space_Coefs_C2_KaHSCR_k_Donut_Space_Coefs_C2_rt_Array_Float_34_20:8.26707172393799, KaHSCR_k_Donut_Space_Coefs_C2_KaHSCR_k_Donut_Space_Coefs_C2_rt_Array_Float_34_21:8.64353656768799, KaHSCR_k_Donut_Space_Coefs_C2_KaHSCR_k_Donut_Space_Coefs_C2_rt_Array_Float_34_22:8.99045372009277, KaHSCR_k_Donut_Space_Coefs_C2_KaHSCR_k_Donut_Space_Coefs_C2_rt_Array_Float_34_23:9.27973079681396, KaHSCR_k_Donut_Space_Coefs_C2_KaHSCR_k_Donut_Space_Coefs_C2_rt_Array_Float_34_24:9.56464672088623, KaHSCR_k_Donut_Space_Coefs_C2_KaHSCR_k_Donut_Space_Coefs_C2_rt_Array_Float_34_25:9.88457489013672, KaHSCR_k_Donut_Space_Coefs_C2_KaHSCR_k_Donut_Space_Coefs_C2_rt_Array_Float_34_26:10.2705402374268, KaHSCR_k_Donut_Space_Coefs_C2_KaHSCR_k_Donut_Space_Coefs_C2_rt_Array_Float_34_27:10.658860206604, KaHSCR_k_Donut_Space_Coefs_C2_KaHSCR_k_Donut_Space_Coefs_C2_rt_Array_Float_34_28:10.8600997924805, KaHSCR_k_Donut_Space_Coefs_C2_KaHSCR_k_Donut_Space_Coefs_C2_rt_Array_Float_34_29:11.1487503051758, KaHSCR_k_Donut_Space_Coefs_C2_KaHSCR_k_Donut_Space_Coefs_C2_rt_Array_Float_34_30:11.4441699981689, KaHSCR_k_Donut_Space_Coefs_C2_KaHSCR_k_Donut_Space_Coefs_C2_rt_Array_Float_34_31:11.6732902526855, KaHSCR_k_Donut_Space_Coefs_C2_KaHSCR_k_Donut_Space_Coefs_C2_rt_Array_Float_34_32:11.8130502700806, KaHSCR_k_Donut_Space_Coefs_C2_KaHSCR_k_Donut_Space_Coefs_C2_rt_Array_Float_34_33:11.9453201293945, KaHSCR_k_Donut_Space_Coefs_C2_KaHSCR_k_Donut_Space_Coefs_C2_rt_Array_Float_34_34:12.0616703033447], parameter=KaHSCR_k_Donut_Space_Coefs_C2}, required-interface=KaHSCR_k_Donut_Space_Coefs_C2
      KaHSCR_k_Donut_Space_Coefs_D: parameter-require-com-spec{init-value=KaHSCR_k_Donut_Space_Coefs_D_KaHSCR_k_Donut_Space_Coefs_D:[KaHSCR_k_Donut_Space_Coefs_D_KaHSCR_k_Donut_Space_Coefs_D_rt_Array_Float_34_1:0.103308998048306, KaHSCR_k_Donut_Space_Coefs_D_KaHSCR_k_Donut_Space_Coefs_D_rt_Array_Float_34_2:0.103308998048306, KaHSCR_k_Donut_Space_Coefs_D_KaHSCR_k_Donut_Space_Coefs_D_rt_Array_Float_34_3:-0.211907997727394, KaHSCR_k_Donut_Space_Coefs_D_KaHSCR_k_Donut_Space_Coefs_D_rt_Array_Float_34_4:-1.20062398910522, KaHSCR_k_Donut_Space_Coefs_D_KaHSCR_k_Donut_Space_Coefs_D_rt_Array_Float_34_5:-2.85137605667114, KaHSCR_k_Donut_Space_Coefs_D_KaHSCR_k_Donut_Space_Coefs_D_rt_Array_Float_34_6:-5.10159778594971, KaHSCR_k_Donut_Space_Coefs_D_KaHSCR_k_Donut_Space_Coefs_D_rt_Array_Float_34_7:-7.90723323822021, KaHSCR_k_Donut_Space_Coefs_D_KaHSCR_k_Donut_Space_Coefs_D_rt_Array_Float_34_8:-10.5811996459961, KaHSCR_k_Donut_Space_Coefs_D_KaHSCR_k_Donut_Space_Coefs_D_rt_Array_Float_34_9:-14.0026197433472, KaHSCR_k_Donut_Space_Coefs_D_KaHSCR_k_Donut_Space_Coefs_D_rt_Array_Float_34_10:-17.6751308441162, KaHSCR_k_Donut_Space_Coefs_D_KaHSCR_k_Donut_Space_Coefs_D_rt_Array_Float_34_11:-21.6737899780273, KaHSCR_k_Donut_Space_Coefs_D_KaHSCR_k_Donut_Space_Coefs_D_rt_Array_Float_34_12:-26.0248203277588, KaHSCR_k_Donut_Space_Coefs_D_KaHSCR_k_Donut_Space_Coefs_D_rt_Array_Float_34_13:-30.7496299743652, KaHSCR_k_Donut_Space_Coefs_D_KaHSCR_k_Donut_Space_Coefs_D_rt_Array_Float_34_14:-35.452018737793, KaHSCR_k_Donut_Space_Coefs_D_KaHSCR_k_Donut_Space_Coefs_D_rt_Array_Float_34_15:-40.3361701965332, KaHSCR_k_Donut_Space_Coefs_D_KaHSCR_k_Donut_Space_Coefs_D_rt_Array_Float_34_16:-45.6424903869629, KaHSCR_k_Donut_Space_Coefs_D_KaHSCR_k_Donut_Space_Coefs_D_rt_Array_Float_34_17:-50.2698593139648, KaHSCR_k_Donut_Space_Coefs_D_KaHSCR_k_Donut_Space_Coefs_D_rt_Array_Float_34_18:-55.375659942627, KaHSCR_k_Donut_Space_Coefs_D_KaHSCR_k_Donut_Space_Coefs_D_rt_Array_Float_34_19:-61.2313995361328, KaHSCR_k_Donut_Space_Coefs_D_KaHSCR_k_Donut_Space_Coefs_D_rt_Array_Float_34_20:-67.2626876831055, KaHSCR_k_Donut_Space_Coefs_D_KaHSCR_k_Donut_Space_Coefs_D_rt_Array_Float_34_21:-73.5646362304688, KaHSCR_k_Donut_Space_Coefs_D_KaHSCR_k_Donut_Space_Coefs_D_rt_Array_Float_34_22:-79.621467590332, KaHSCR_k_Donut_Space_Coefs_D_KaHSCR_k_Donut_Space_Coefs_D_rt_Array_Float_34_23:-84.9908294677734, KaHSCR_k_Donut_Space_Coefs_D_KaHSCR_k_Donut_Space_Coefs_D_rt_Array_Float_34_24:-90.269172668457, KaHSCR_k_Donut_Space_Coefs_D_KaHSCR_k_Donut_Space_Coefs_D_rt_Array_Float_34_25:-96.3239364624023, KaHSCR_k_Donut_Space_Coefs_D_KaHSCR_k_Donut_Space_Coefs_D_rt_Array_Float_34_26:-104.145500183105, KaHSCR_k_Donut_Space_Coefs_D_KaHSCR_k_Donut_Space_Coefs_D_rt_Array_Float_34_27:-112.130699157715, KaHSCR_k_Donut_Space_Coefs_D_KaHSCR_k_Donut_Space_Coefs_D_rt_Array_Float_34_28:-116.38639831543, KaHSCR_k_Donut_Space_Coefs_D_KaHSCR_k_Donut_Space_Coefs_D_rt_Array_Float_34_29:-122.710998535156, KaHSCR_k_Donut_Space_Coefs_D_KaHSCR_k_Donut_Space_Coefs_D_rt_Array_Float_34_30:-129.441192626953, KaHSCR_k_Donut_Space_Coefs_D_KaHSCR_k_Donut_Space_Coefs_D_rt_Array_Float_34_31:-134.5126953125, KaHSCR_k_Donut_Space_Coefs_D_KaHSCR_k_Donut_Space_Coefs_D_rt_Array_Float_34_32:-137.768402099609, KaHSCR_k_Donut_Space_Coefs_D_KaHSCR_k_Donut_Space_Coefs_D_rt_Array_Float_34_33:-140.760498046875, KaHSCR_k_Donut_Space_Coefs_D_KaHSCR_k_Donut_Space_Coefs_D_rt_Array_Float_34_34:-143.608093261719], parameter=KaHSCR_k_Donut_Space_Coefs_D}, required-interface=KaHSCR_k_Donut_Space_Coefs_D
      KaHSCR_k_Donut_Space_Coefs_E: parameter-require-com-spec{init-value=KaHSCR_k_Donut_Space_Coefs_E_KaHSCR_k_Donut_Space_Coefs_E:[KaHSCR_k_Donut_Space_Coefs_E_KaHSCR_k_Donut_Space_Coefs_E_rt_Array_Float_34_1:0.103308998048306, KaHSCR_k_Donut_Space_Coefs_E_KaHSCR_k_Donut_Space_Coefs_E_rt_Array_Float_34_2:0.103308998048306, KaHSCR_k_Donut_Space_Coefs_E_KaHSCR_k_Donut_Space_Coefs_E_rt_Array_Float_34_3:-0.211907997727394, KaHSCR_k_Donut_Space_Coefs_E_KaHSCR_k_Donut_Space_Coefs_E_rt_Array_Float_34_4:-1.20062398910522, KaHSCR_k_Donut_Space_Coefs_E_KaHSCR_k_Donut_Space_Coefs_E_rt_Array_Float_34_5:-2.85137605667114, KaHSCR_k_Donut_Space_Coefs_E_KaHSCR_k_Donut_Space_Coefs_E_rt_Array_Float_34_6:-5.10159778594971, KaHSCR_k_Donut_Space_Coefs_E_KaHSCR_k_Donut_Space_Coefs_E_rt_Array_Float_34_7:-7.90723323822021, KaHSCR_k_Donut_Space_Coefs_E_KaHSCR_k_Donut_Space_Coefs_E_rt_Array_Float_34_8:-10.5811996459961, KaHSCR_k_Donut_Space_Coefs_E_KaHSCR_k_Donut_Space_Coefs_E_rt_Array_Float_34_9:-14.0026197433472, KaHSCR_k_Donut_Space_Coefs_E_KaHSCR_k_Donut_Space_Coefs_E_rt_Array_Float_34_10:-17.6751308441162, KaHSCR_k_Donut_Space_Coefs_E_KaHSCR_k_Donut_Space_Coefs_E_rt_Array_Float_34_11:-21.6737899780273, KaHSCR_k_Donut_Space_Coefs_E_KaHSCR_k_Donut_Space_Coefs_E_rt_Array_Float_34_12:-26.0248203277588, KaHSCR_k_Donut_Space_Coefs_E_KaHSCR_k_Donut_Space_Coefs_E_rt_Array_Float_34_13:-30.7496299743652, KaHSCR_k_Donut_Space_Coefs_E_KaHSCR_k_Donut_Space_Coefs_E_rt_Array_Float_34_14:-35.452018737793, KaHSCR_k_Donut_Space_Coefs_E_KaHSCR_k_Donut_Space_Coefs_E_rt_Array_Float_34_15:-40.3361701965332, KaHSCR_k_Donut_Space_Coefs_E_KaHSCR_k_Donut_Space_Coefs_E_rt_Array_Float_34_16:-45.6424903869629, KaHSCR_k_Donut_Space_Coefs_E_KaHSCR_k_Donut_Space_Coefs_E_rt_Array_Float_34_17:-50.2698593139648, KaHSCR_k_Donut_Space_Coefs_E_KaHSCR_k_Donut_Space_Coefs_E_rt_Array_Float_34_18:-55.375659942627, KaHSCR_k_Donut_Space_Coefs_E_KaHSCR_k_Donut_Space_Coefs_E_rt_Array_Float_34_19:-61.2313995361328, KaHSCR_k_Donut_Space_Coefs_E_KaHSCR_k_Donut_Space_Coefs_E_rt_Array_Float_34_20:-67.2626876831055, KaHSCR_k_Donut_Space_Coefs_E_KaHSCR_k_Donut_Space_Coefs_E_rt_Array_Float_34_21:-73.5646362304688, KaHSCR_k_Donut_Space_Coefs_E_KaHSCR_k_Donut_Space_Coefs_E_rt_Array_Float_34_22:-79.621467590332, KaHSCR_k_Donut_Space_Coefs_E_KaHSCR_k_Donut_Space_Coefs_E_rt_Array_Float_34_23:-84.9908294677734, KaHSCR_k_Donut_Space_Coefs_E_KaHSCR_k_Donut_Space_Coefs_E_rt_Array_Float_34_24:-90.269172668457, KaHSCR_k_Donut_Space_Coefs_E_KaHSCR_k_Donut_Space_Coefs_E_rt_Array_Float_34_25:-96.3239364624023, KaHSCR_k_Donut_Space_Coefs_E_KaHSCR_k_Donut_Space_Coefs_E_rt_Array_Float_34_26:-104.145500183105, KaHSCR_k_Donut_Space_Coefs_E_KaHSCR_k_Donut_Space_Coefs_E_rt_Array_Float_34_27:-112.130699157715, KaHSCR_k_Donut_Space_Coefs_E_KaHSCR_k_Donut_Space_Coefs_E_rt_Array_Float_34_28:-116.38639831543, KaHSCR_k_Donut_Space_Coefs_E_KaHSCR_k_Donut_Space_Coefs_E_rt_Array_Float_34_29:-122.710998535156, KaHSCR_k_Donut_Space_Coefs_E_KaHSCR_k_Donut_Space_Coefs_E_rt_Array_Float_34_30:-129.441192626953, KaHSCR_k_Donut_Space_Coefs_E_KaHSCR_k_Donut_Space_Coefs_E_rt_Array_Float_34_31:-134.5126953125, KaHSCR_k_Donut_Space_Coefs_E_KaHSCR_k_Donut_Space_Coefs_E_rt_Array_Float_34_32:-137.768402099609, KaHSCR_k_Donut_Space_Coefs_E_KaHSCR_k_Donut_Space_Coefs_E_rt_Array_Float_34_33:-140.760498046875, KaHSCR_k_Donut_Space_Coefs_E_KaHSCR_k_Donut_Space_Coefs_E_rt_Array_Float_34_34:-143.608093261719], parameter=KaHSCR_k_Donut_Space_Coefs_E}, required-interface=KaHSCR_k_Donut_Space_Coefs_E
      KaHSCR_n_DonutSpaceCoeffs_AxisA: parameter-require-com-spec{init-value=KaHSCR_n_DonutSpaceCoeffs_AxisA_KaHSCR_n_DonutSpaceCoeffs_AxisA:[KaHSCR_n_DonutSpaceCoeffs_AxisA_KaHSCR_n_DonutSpaceCoeffs_AxisA_rt_Array_Float_34_1:0.00100000004749745, KaHSCR_n_DonutSpaceCoeffs_AxisA_KaHSCR_n_DonutSpaceCoeffs_AxisA_rt_Array_Float_34_2:100, KaHSCR_n_DonutSpaceCoeffs_AxisA_KaHSCR_n_DonutSpaceCoeffs_AxisA_rt_Array_Float_34_3:250, KaHSCR_n_DonutSpaceCoeffs_AxisA_KaHSCR_n_DonutSpaceCoeffs_AxisA_rt_Array_Float_34_4:500, KaHSCR_n_DonutSpaceCoeffs_AxisA_KaHSCR_n_DonutSpaceCoeffs_AxisA_rt_Array_Float_34_5:750, KaHSCR_n_DonutSpaceCoeffs_AxisA_KaHSCR_n_DonutSpaceCoeffs_AxisA_rt_Array_Float_34_6:1000, KaHSCR_n_DonutSpaceCoeffs_AxisA_KaHSCR_n_DonutSpaceCoeffs_AxisA_rt_Array_Float_34_7:1250, KaHSCR_n_DonutSpaceCoeffs_AxisA_KaHSCR_n_DonutSpaceCoeffs_AxisA_rt_Array_Float_34_8:1500, KaHSCR_n_DonutSpaceCoeffs_AxisA_KaHSCR_n_DonutSpaceCoeffs_AxisA_rt_Array_Float_34_9:1750, KaHSCR_n_DonutSpaceCoeffs_AxisA_KaHSCR_n_DonutSpaceCoeffs_AxisA_rt_Array_Float_34_10:2000, KaHSCR_n_DonutSpaceCoeffs_AxisA_KaHSCR_n_DonutSpaceCoeffs_AxisA_rt_Array_Float_34_11:2250, KaHSCR_n_DonutSpaceCoeffs_AxisA_KaHSCR_n_DonutSpaceCoeffs_AxisA_rt_Array_Float_34_12:2500, KaHSCR_n_DonutSpaceCoeffs_AxisA_KaHSCR_n_DonutSpaceCoeffs_AxisA_rt_Array_Float_34_13:2750, KaHSCR_n_DonutSpaceCoeffs_AxisA_KaHSCR_n_DonutSpaceCoeffs_AxisA_rt_Array_Float_34_14:3000, KaHSCR_n_DonutSpaceCoeffs_AxisA_KaHSCR_n_DonutSpaceCoeffs_AxisA_rt_Array_Float_34_15:3250, KaHSCR_n_DonutSpaceCoeffs_AxisA_KaHSCR_n_DonutSpaceCoeffs_AxisA_rt_Array_Float_34_16:3500, KaHSCR_n_DonutSpaceCoeffs_AxisA_KaHSCR_n_DonutSpaceCoeffs_AxisA_rt_Array_Float_34_17:3750, KaHSCR_n_DonutSpaceCoeffs_AxisA_KaHSCR_n_DonutSpaceCoeffs_AxisA_rt_Array_Float_34_18:4000, KaHSCR_n_DonutSpaceCoeffs_AxisA_KaHSCR_n_DonutSpaceCoeffs_AxisA_rt_Array_Float_34_19:4250, KaHSCR_n_DonutSpaceCoeffs_AxisA_KaHSCR_n_DonutSpaceCoeffs_AxisA_rt_Array_Float_34_20:4500, KaHSCR_n_DonutSpaceCoeffs_AxisA_KaHSCR_n_DonutSpaceCoeffs_AxisA_rt_Array_Float_34_21:4750, KaHSCR_n_DonutSpaceCoeffs_AxisA_KaHSCR_n_DonutSpaceCoeffs_AxisA_rt_Array_Float_34_22:5000, KaHSCR_n_DonutSpaceCoeffs_AxisA_KaHSCR_n_DonutSpaceCoeffs_AxisA_rt_Array_Float_34_23:5250, KaHSCR_n_DonutSpaceCoeffs_AxisA_KaHSCR_n_DonutSpaceCoeffs_AxisA_rt_Array_Float_34_24:5500, KaHSCR_n_DonutSpaceCoeffs_AxisA_KaHSCR_n_DonutSpaceCoeffs_AxisA_rt_Array_Float_34_25:5750, KaHSCR_n_DonutSpaceCoeffs_AxisA_KaHSCR_n_DonutSpaceCoeffs_AxisA_rt_Array_Float_34_26:6000, KaHSCR_n_DonutSpaceCoeffs_AxisA_KaHSCR_n_DonutSpaceCoeffs_AxisA_rt_Array_Float_34_27:6250, KaHSCR_n_DonutSpaceCoeffs_AxisA_KaHSCR_n_DonutSpaceCoeffs_AxisA_rt_Array_Float_34_28:6500, KaHSCR_n_DonutSpaceCoeffs_AxisA_KaHSCR_n_DonutSpaceCoeffs_AxisA_rt_Array_Float_34_29:7000, KaHSCR_n_DonutSpaceCoeffs_AxisA_KaHSCR_n_DonutSpaceCoeffs_AxisA_rt_Array_Float_34_30:7500, KaHSCR_n_DonutSpaceCoeffs_AxisA_KaHSCR_n_DonutSpaceCoeffs_AxisA_rt_Array_Float_34_31:8000, KaHSCR_n_DonutSpaceCoeffs_AxisA_KaHSCR_n_DonutSpaceCoeffs_AxisA_rt_Array_Float_34_32:8500, KaHSCR_n_DonutSpaceCoeffs_AxisA_KaHSCR_n_DonutSpaceCoeffs_AxisA_rt_Array_Float_34_33:9000, KaHSCR_n_DonutSpaceCoeffs_AxisA_KaHSCR_n_DonutSpaceCoeffs_AxisA_rt_Array_Float_34_34:10500], parameter=KaHSCR_n_DonutSpaceCoeffs_AxisA}, required-interface=KaHSCR_n_DonutSpaceCoeffs_AxisA
      KaHSCR_n_DonutSpaceCoeffs_AxisB: parameter-require-com-spec{init-value=KaHSCR_n_DonutSpaceCoeffs_AxisB_KaHSCR_n_DonutSpaceCoeffs_AxisB:[KaHSCR_n_DonutSpaceCoeffs_AxisB_KaHSCR_n_DonutSpaceCoeffs_AxisB_rt_Array_Float_34_1:0.00100000004749745, KaHSCR_n_DonutSpaceCoeffs_AxisB_KaHSCR_n_DonutSpaceCoeffs_AxisB_rt_Array_Float_34_2:100, KaHSCR_n_DonutSpaceCoeffs_AxisB_KaHSCR_n_DonutSpaceCoeffs_AxisB_rt_Array_Float_34_3:250, KaHSCR_n_DonutSpaceCoeffs_AxisB_KaHSCR_n_DonutSpaceCoeffs_AxisB_rt_Array_Float_34_4:500, KaHSCR_n_DonutSpaceCoeffs_AxisB_KaHSCR_n_DonutSpaceCoeffs_AxisB_rt_Array_Float_34_5:750, KaHSCR_n_DonutSpaceCoeffs_AxisB_KaHSCR_n_DonutSpaceCoeffs_AxisB_rt_Array_Float_34_6:1000, KaHSCR_n_DonutSpaceCoeffs_AxisB_KaHSCR_n_DonutSpaceCoeffs_AxisB_rt_Array_Float_34_7:1250, KaHSCR_n_DonutSpaceCoeffs_AxisB_KaHSCR_n_DonutSpaceCoeffs_AxisB_rt_Array_Float_34_8:1500, KaHSCR_n_DonutSpaceCoeffs_AxisB_KaHSCR_n_DonutSpaceCoeffs_AxisB_rt_Array_Float_34_9:1750, KaHSCR_n_DonutSpaceCoeffs_AxisB_KaHSCR_n_DonutSpaceCoeffs_AxisB_rt_Array_Float_34_10:2000, KaHSCR_n_DonutSpaceCoeffs_AxisB_KaHSCR_n_DonutSpaceCoeffs_AxisB_rt_Array_Float_34_11:2250, KaHSCR_n_DonutSpaceCoeffs_AxisB_KaHSCR_n_DonutSpaceCoeffs_AxisB_rt_Array_Float_34_12:2500, KaHSCR_n_DonutSpaceCoeffs_AxisB_KaHSCR_n_DonutSpaceCoeffs_AxisB_rt_Array_Float_34_13:2750, KaHSCR_n_DonutSpaceCoeffs_AxisB_KaHSCR_n_DonutSpaceCoeffs_AxisB_rt_Array_Float_34_14:3000, KaHSCR_n_DonutSpaceCoeffs_AxisB_KaHSCR_n_DonutSpaceCoeffs_AxisB_rt_Array_Float_34_15:3250, KaHSCR_n_DonutSpaceCoeffs_AxisB_KaHSCR_n_DonutSpaceCoeffs_AxisB_rt_Array_Float_34_16:3500, KaHSCR_n_DonutSpaceCoeffs_AxisB_KaHSCR_n_DonutSpaceCoeffs_AxisB_rt_Array_Float_34_17:3750, KaHSCR_n_DonutSpaceCoeffs_AxisB_KaHSCR_n_DonutSpaceCoeffs_AxisB_rt_Array_Float_34_18:4000, KaHSCR_n_DonutSpaceCoeffs_AxisB_KaHSCR_n_DonutSpaceCoeffs_AxisB_rt_Array_Float_34_19:4250, KaHSCR_n_DonutSpaceCoeffs_AxisB_KaHSCR_n_DonutSpaceCoeffs_AxisB_rt_Array_Float_34_20:4500, KaHSCR_n_DonutSpaceCoeffs_AxisB_KaHSCR_n_DonutSpaceCoeffs_AxisB_rt_Array_Float_34_21:4750, KaHSCR_n_DonutSpaceCoeffs_AxisB_KaHSCR_n_DonutSpaceCoeffs_AxisB_rt_Array_Float_34_22:5000, KaHSCR_n_DonutSpaceCoeffs_AxisB_KaHSCR_n_DonutSpaceCoeffs_AxisB_rt_Array_Float_34_23:5250, KaHSCR_n_DonutSpaceCoeffs_AxisB_KaHSCR_n_DonutSpaceCoeffs_AxisB_rt_Array_Float_34_24:5500, KaHSCR_n_DonutSpaceCoeffs_AxisB_KaHSCR_n_DonutSpaceCoeffs_AxisB_rt_Array_Float_34_25:5750, KaHSCR_n_DonutSpaceCoeffs_AxisB_KaHSCR_n_DonutSpaceCoeffs_AxisB_rt_Array_Float_34_26:6000, KaHSCR_n_DonutSpaceCoeffs_AxisB_KaHSCR_n_DonutSpaceCoeffs_AxisB_rt_Array_Float_34_27:6250, KaHSCR_n_DonutSpaceCoeffs_AxisB_KaHSCR_n_DonutSpaceCoeffs_AxisB_rt_Array_Float_34_28:6500, KaHSCR_n_DonutSpaceCoeffs_AxisB_KaHSCR_n_DonutSpaceCoeffs_AxisB_rt_Array_Float_34_29:7000, KaHSCR_n_DonutSpaceCoeffs_AxisB_KaHSCR_n_DonutSpaceCoeffs_AxisB_rt_Array_Float_34_30:7500, KaHSCR_n_DonutSpaceCoeffs_AxisB_KaHSCR_n_DonutSpaceCoeffs_AxisB_rt_Array_Float_34_31:8000, KaHSCR_n_DonutSpaceCoeffs_AxisB_KaHSCR_n_DonutSpaceCoeffs_AxisB_rt_Array_Float_34_32:8500, KaHSCR_n_DonutSpaceCoeffs_AxisB_KaHSCR_n_DonutSpaceCoeffs_AxisB_rt_Array_Float_34_33:9000, KaHSCR_n_DonutSpaceCoeffs_AxisB_KaHSCR_n_DonutSpaceCoeffs_AxisB_rt_Array_Float_34_34:10500], parameter=KaHSCR_n_DonutSpaceCoeffs_AxisB}, required-interface=KaHSCR_n_DonutSpaceCoeffs_AxisB
      KaHSCR_n_DonutSpaceCoeffs_AxisC: parameter-require-com-spec{init-value=KaHSCR_n_DonutSpaceCoeffs_AxisC_KaHSCR_n_DonutSpaceCoeffs_AxisC:[KaHSCR_n_DonutSpaceCoeffs_AxisC_KaHSCR_n_DonutSpaceCoeffs_AxisC_rt_Array_Float_34_1:0.00100000004749745, KaHSCR_n_DonutSpaceCoeffs_AxisC_KaHSCR_n_DonutSpaceCoeffs_AxisC_rt_Array_Float_34_2:100, KaHSCR_n_DonutSpaceCoeffs_AxisC_KaHSCR_n_DonutSpaceCoeffs_AxisC_rt_Array_Float_34_3:250, KaHSCR_n_DonutSpaceCoeffs_AxisC_KaHSCR_n_DonutSpaceCoeffs_AxisC_rt_Array_Float_34_4:500, KaHSCR_n_DonutSpaceCoeffs_AxisC_KaHSCR_n_DonutSpaceCoeffs_AxisC_rt_Array_Float_34_5:750, KaHSCR_n_DonutSpaceCoeffs_AxisC_KaHSCR_n_DonutSpaceCoeffs_AxisC_rt_Array_Float_34_6:1000, KaHSCR_n_DonutSpaceCoeffs_AxisC_KaHSCR_n_DonutSpaceCoeffs_AxisC_rt_Array_Float_34_7:1250, KaHSCR_n_DonutSpaceCoeffs_AxisC_KaHSCR_n_DonutSpaceCoeffs_AxisC_rt_Array_Float_34_8:1500, KaHSCR_n_DonutSpaceCoeffs_AxisC_KaHSCR_n_DonutSpaceCoeffs_AxisC_rt_Array_Float_34_9:1750, KaHSCR_n_DonutSpaceCoeffs_AxisC_KaHSCR_n_DonutSpaceCoeffs_AxisC_rt_Array_Float_34_10:2000, KaHSCR_n_DonutSpaceCoeffs_AxisC_KaHSCR_n_DonutSpaceCoeffs_AxisC_rt_Array_Float_34_11:2250, KaHSCR_n_DonutSpaceCoeffs_AxisC_KaHSCR_n_DonutSpaceCoeffs_AxisC_rt_Array_Float_34_12:2500, KaHSCR_n_DonutSpaceCoeffs_AxisC_KaHSCR_n_DonutSpaceCoeffs_AxisC_rt_Array_Float_34_13:2750, KaHSCR_n_DonutSpaceCoeffs_AxisC_KaHSCR_n_DonutSpaceCoeffs_AxisC_rt_Array_Float_34_14:3000, KaHSCR_n_DonutSpaceCoeffs_AxisC_KaHSCR_n_DonutSpaceCoeffs_AxisC_rt_Array_Float_34_15:3250, KaHSCR_n_DonutSpaceCoeffs_AxisC_KaHSCR_n_DonutSpaceCoeffs_AxisC_rt_Array_Float_34_16:3500, KaHSCR_n_DonutSpaceCoeffs_AxisC_KaHSCR_n_DonutSpaceCoeffs_AxisC_rt_Array_Float_34_17:3750, KaHSCR_n_DonutSpaceCoeffs_AxisC_KaHSCR_n_DonutSpaceCoeffs_AxisC_rt_Array_Float_34_18:4000, KaHSCR_n_DonutSpaceCoeffs_AxisC_KaHSCR_n_DonutSpaceCoeffs_AxisC_rt_Array_Float_34_19:4250, KaHSCR_n_DonutSpaceCoeffs_AxisC_KaHSCR_n_DonutSpaceCoeffs_AxisC_rt_Array_Float_34_20:4500, KaHSCR_n_DonutSpaceCoeffs_AxisC_KaHSCR_n_DonutSpaceCoeffs_AxisC_rt_Array_Float_34_21:4750, KaHSCR_n_DonutSpaceCoeffs_AxisC_KaHSCR_n_DonutSpaceCoeffs_AxisC_rt_Array_Float_34_22:5000, KaHSCR_n_DonutSpaceCoeffs_AxisC_KaHSCR_n_DonutSpaceCoeffs_AxisC_rt_Array_Float_34_23:5250, KaHSCR_n_DonutSpaceCoeffs_AxisC_KaHSCR_n_DonutSpaceCoeffs_AxisC_rt_Array_Float_34_24:5500, KaHSCR_n_DonutSpaceCoeffs_AxisC_KaHSCR_n_DonutSpaceCoeffs_AxisC_rt_Array_Float_34_25:5750, KaHSCR_n_DonutSpaceCoeffs_AxisC_KaHSCR_n_DonutSpaceCoeffs_AxisC_rt_Array_Float_34_26:6000, KaHSCR_n_DonutSpaceCoeffs_AxisC_KaHSCR_n_DonutSpaceCoeffs_AxisC_rt_Array_Float_34_27:6250, KaHSCR_n_DonutSpaceCoeffs_AxisC_KaHSCR_n_DonutSpaceCoeffs_AxisC_rt_Array_Float_34_28:6500, KaHSCR_n_DonutSpaceCoeffs_AxisC_KaHSCR_n_DonutSpaceCoeffs_AxisC_rt_Array_Float_34_29:7000, KaHSCR_n_DonutSpaceCoeffs_AxisC_KaHSCR_n_DonutSpaceCoeffs_AxisC_rt_Array_Float_34_30:7500, KaHSCR_n_DonutSpaceCoeffs_AxisC_KaHSCR_n_DonutSpaceCoeffs_AxisC_rt_Array_Float_34_31:8000, KaHSCR_n_DonutSpaceCoeffs_AxisC_KaHSCR_n_DonutSpaceCoeffs_AxisC_rt_Array_Float_34_32:8500, KaHSCR_n_DonutSpaceCoeffs_AxisC_KaHSCR_n_DonutSpaceCoeffs_AxisC_rt_Array_Float_34_33:9000, KaHSCR_n_DonutSpaceCoeffs_AxisC_KaHSCR_n_DonutSpaceCoeffs_AxisC_rt_Array_Float_34_34:10500], parameter=KaHSCR_n_DonutSpaceCoeffs_AxisC}, required-interface=KaHSCR_n_DonutSpaceCoeffs_AxisC
      KeTSXR_D_ExternWEDMtrDmpng: parameter-require-com-spec{init-value=KeTSXR_D_ExternWEDMtrDmpng_KeTSXR_D_ExternWEDMtrDmpng:1, parameter=KeTSXR_D_ExternWEDMtrDmpng}, required-interface=KeTSXR_D_ExternWEDMtrDmpng
      KeTSXR_J_ExternWEDMtrInertia: parameter-require-com-spec{init-value=KeTSXR_J_ExternWEDMtrInertia_KeTSXR_J_ExternWEDMtrInertia:1, parameter=KeTSXR_J_ExternWEDMtrInertia}, required-interface=KeTSXR_J_ExternWEDMtrInertia
      KeTSXR_J_Ia: parameter-require-com-spec{init-value=KeTSXR_J_Ia_KeTSXR_J_Ia:0.00136836851015687, parameter=KeTSXR_J_Ia}, required-interface=KeTSXR_J_Ia
      KeTSXR_J_Ib: parameter-require-com-spec{init-value=KeTSXR_J_Ib_KeTSXR_J_Ib:0.0059690261259675026, parameter=KeTSXR_J_Ib}, required-interface=KeTSXR_J_Ib
      HeTSXR_e_NxDomain: parameter-require-com-spec{init-value=CeTSXR_e_Nx_Nb, parameter=HeTSXR_e_NxDomain}, required-interface=HeTSXR_e_NxDomain
    behavior IB_ADCR: data-type-mapping=msADTtoIDTMapping, handle-termination-and-restart=NO-SUPPORT, included-data-type-set=data-type=[TeADCR_e_AWDDiscProfEqn, TeADCR_e_AWDDiscSlipSpdEqn, TeADCR_e_AWDReqArb, TeADCR_e_WEDPriority, TeADCR_e_WEDStGrp]
      4 x timing event:
        Event_MedTEB1: start-on-event=ADCR_MedTEB1, period=0.01
        Event_MedTED1: start-on-event=ADCR_MedTED1, period=0.02
        Event_MedTED2: start-on-event=ADCR_MedTED2, period=0.02
        Event_MedTEB2: start-on-event=ADCR_MedTEB2, period=0.01
      init event Event_ADCR_ac_Init: start-on-event=ADCR_ac_Init
      init event Event_PwrOn: start-on-event=ADCR_PwrOn
      explicit-inter-runnable-variables:
        8 x data, all with category=VALUE, sw-calibration-access=READ-ONLY:
          VeADCC_b_ClchLocked_IRV: type=Boolean, init-value=0
          VeADCC_e_AWDClchXStat_IRV: type=TeADCR_e_AWDClchStat, init-value=CeADCR_e_Released
          VeADCC_e_AWDClchYStat_IRV: type=TeADCR_e_AWDClchStat, init-value=CeADCR_e_Released
          VeADCC_m_WEDThruTorq_IRV: type=Float, init-value=0
          VeADCR_n_NxAct_IRV: type=Float, init-value=0
          VeADCR_dn_NxDotAct_IRV: type=Float, init-value=0
          VeADCR_e_AWDClchXRawStat_IRV: type=TeADCR_e_WEDStatus, init-value=CeADCR_e_Init
          VeADCR_e_AWDClchYRawStat_IRV: type=TeADCR_e_WEDStatus, init-value=CeADCR_e_Init
      6 x runnable:
        ADCR_ac_Init
          data-send-points:
            11 x access:
              OUT_VeADCR_e_WEDLeftStat_Value: accessed-variable=VeADCR_e_WEDLeftStat.Value
              OUT_VeADCR_e_WEDRightStat_Value: accessed-variable=VeADCR_e_WEDRightStat.Value
              OUT_VeADCR_e_WEDLftCmndStat_Value: accessed-variable=VeADCR_e_WEDLftCmndStat.Value
              OUT_VeADCR_e_WEDRtCmndStat_Value: accessed-variable=VeADCR_e_WEDRtCmndStat.Value
              OUT_VeADCR_e_WEDCmndArb_Value: accessed-variable=VeADCR_e_WEDCmndArb.Value
              OUT_VeADCR_e_WEDAxleStat_Value: accessed-variable=VeADCR_e_WEDAxleStat.Value
              OUT_VeADCR_e_WEDLeftCmndMgrSt_Value: accessed-variable=VeADCR_e_WEDLeftCmndMgrSt.Value
              OUT_VeADCR_e_WEDRightCmndMgrSt_Value: accessed-variable=VeADCR_e_WEDRightCmndMgrSt.Value
              OUT_VeADCR_e_AWDSysStat_Value: accessed-variable=VeADCR_e_AWDSysStat.Value
              OUT_VeADCR_e_AWDDiscCurrSt_Value: accessed-variable=VeADCR_e_AWDDiscCurrSt.Value
              OUT_VeADCR_i_WEDCmndArbPrioLvl_Value: accessed-variable=VeADCR_i_WEDCmndArbPrioLvl.Value
        ADCR_PwrOn
          data-send-points:
            30 x access:
              OUT_VeADCR_e_WEDLeftStat_Value: accessed-variable=VeADCR_e_WEDLeftStat.Value
              OUT_VeADCR_e_WEDRightStat_Value: accessed-variable=VeADCR_e_WEDRightStat.Value
              OUT_VeADCR_e_WEDLftCmndStat_Value: accessed-variable=VeADCR_e_WEDLftCmndStat.Value
              OUT_VeADCR_e_WEDRtCmndStat_Value: accessed-variable=VeADCR_e_WEDRtCmndStat.Value
              OUT_VeADCR_M_WEDMtrCLMax_Value: accessed-variable=VeADCR_M_WEDMtrCLMax.Value
              OUT_VeADCR_M_WEDMtrCLMin_Value: accessed-variable=VeADCR_M_WEDMtrCLMin.Value
              OUT_VeADCR_e_WEDCmndArb_Value: accessed-variable=VeADCR_e_WEDCmndArb.Value
              OUT_VeADCR_Cnt_LftWEDClsngAttempts_Value: accessed-variable=VeADCR_Cnt_LftWEDClsngAttempts.Value
              OUT_VeADCR_Cnt_LftWEDOpngAttempts_Value: accessed-variable=VeADCR_Cnt_LftWEDOpngAttempts.Value
              OUT_VeADCR_Cnt_RtWEDClsngAttempts_Value: accessed-variable=VeADCR_Cnt_RtWEDClsngAttempts.Value
              OUT_VeADCR_Cnt_RtWEDOpngAttempts_Value: accessed-variable=VeADCR_Cnt_RtWEDOpngAttempts.Value
              OUT_VeADCR_e_WEDAxleStat_Value: accessed-variable=VeADCR_e_WEDAxleStat.Value
              OUT_VeADCR_i_WEDAxleStat_CAN_Value: accessed-variable=VeADCR_i_WEDAxleStat_CAN.Value
              OUT_VeADCR_e_WEDLeftCmndMgrSt_Value: accessed-variable=VeADCR_e_WEDLeftCmndMgrSt.Value
              OUT_VeADCR_e_WEDRightCmndMgrSt_Value: accessed-variable=VeADCR_e_WEDRightCmndMgrSt.Value
              OUT_VeADCR_n_AWDNxTgt_Value: accessed-variable=VeADCR_n_AWDNxTgt.Value
              OUT_VeADCR_dn_AWDNxTgtDot_Value: accessed-variable=VeADCR_dn_AWDNxTgtDot.Value
              OUT_VeADCR_M_AWDClch_TcR_Ovrd_Value: accessed-variable=VeADCR_M_AWDClch_TcR_Ovrd.Value
              OUT_VeADCR_M_AWDClch_LeadTcR_Ovrd_Value: accessed-variable=VeADCR_M_AWDClch_LeadTcR_Ovrd.Value
              OUT_VeADCR_b_AWDUseLckedEqn_Value: accessed-variable=VeADCR_b_AWDUseLckedEqn.Value
              OUT_VeADCR_k_AWDNxProfFilt_Value: accessed-variable=VeADCR_k_AWDNxProfFilt.Value
              OUT_VeADCR_M_AWDClch_TorqEst_Value: accessed-variable=VeADCR_M_AWDClch_TorqEst.Value
              OUT_VeADCR_b_ADCOfldCnfm_Value: accessed-variable=VeADCR_b_ADCOfldCnfm.Value
              OUT_VeADCR_b_WiggleRequest_Value: accessed-variable=VeADCR_b_WiggleRequest.Value
              OUT_VeADCR_e_AWDSysStat_Value: accessed-variable=VeADCR_e_AWDSysStat.Value
              OUT_VeADCR_P_PwrRsrv4EngmtRaw_Value: accessed-variable=VeADCR_P_PwrRsrv4EngmtRaw.Value
              OUT_VeADCR_P_PwrRsrv4Engmt_Value: accessed-variable=VeADCR_P_PwrRsrv4Engmt.Value
              OUT_VeADCR_P_PwrRsrv4EngmtLead_Value: accessed-variable=VeADCR_P_PwrRsrv4EngmtLead.Value
              OUT_VeADCR_e_AWDDiscCurrSt_Value: accessed-variable=VeADCR_e_AWDDiscCurrSt.Value
              OUT_VeADCR_i_WEDCmndArbPrioLvl_Value: accessed-variable=VeADCR_i_WEDCmndArbPrioLvl.Value
          written-local-variables:
            8 x access:
              WV_VeADCC_b_ClchLocked_IRV: accessed-variable=VeADCC_b_ClchLocked_IRV
              WV_VeADCC_m_WEDThruTorq_IRV: accessed-variable=VeADCC_m_WEDThruTorq_IRV
              WV_VeADCR_dn_NxDotAct_IRV: accessed-variable=VeADCR_dn_NxDotAct_IRV
              WV_VeADCR_e_AWDClchXRawStat_IRV: accessed-variable=VeADCR_e_AWDClchXRawStat_IRV
              WV_VeADCC_e_AWDClchXStat_IRV: accessed-variable=VeADCC_e_AWDClchXStat_IRV
              WV_VeADCR_e_AWDClchYRawStat_IRV: accessed-variable=VeADCR_e_AWDClchYRawStat_IRV
              WV_VeADCC_e_AWDClchYStat_IRV: accessed-variable=VeADCC_e_AWDClchYStat_IRV
              WV_VeADCR_n_NxAct_IRV: accessed-variable=VeADCR_n_NxAct_IRV
        ADCR_MedTEB1
          data-receive-point-by-arguments:
            24 x access:
              IN_VeADAR_L_LftSlndPos_Value: accessed-variable=VeADAR_L_LftSlndPos.Value, variation-point={short-label=vpIN_VeADAR_L_LftSlndPos_Value, sw-syscond=1}
              IN_VeADAR_L_RtSlndPos_Value: accessed-variable=VeADAR_L_RtSlndPos.Value, variation-point={short-label=vpIN_VeADAR_L_RtSlndPos_Value, sw-syscond=1}
              IN_VeADAR_b_CoolDownActiveLftWED_Value: accessed-variable=VeADAR_b_CoolDownActiveLftWED.Value, variation-point={short-label=vpIN_VeADAR_b_CoolDownActiveLftWED_Value, sw-syscond=1}
              IN_VeADAR_b_CoolDownActiveRtWED_Value: accessed-variable=VeADAR_b_CoolDownActiveRtWED.Value, variation-point={short-label=vpIN_VeADAR_b_CoolDownActiveRtWED_Value, sw-syscond=1}
              IN_VeADAR_e_LeftActuationStatus_Value: accessed-variable=VeADAR_e_LeftActuationStatus.Value, variation-point={short-label=vpIN_VeADAR_e_LeftActuationStatus_Value, sw-syscond=1}
              IN_VeADAR_e_RightActuationStatus_Value: accessed-variable=VeADAR_e_RightActuationStatus.Value, variation-point={short-label=vpIN_VeADAR_e_RightActuationStatus_Value, sw-syscond=1}
              IN_VeADIR_b_LftWEDClosingFail_Value: accessed-variable=VeADIR_b_LftWEDClosingFail.Value, variation-point={short-label=vpIN_VeADIR_b_LftWEDClosingFail_Value, sw-syscond=1}
              IN_VeADIR_b_LftWEDOpeningFail_Value: accessed-variable=VeADIR_b_LftWEDOpeningFail.Value, variation-point={short-label=vpIN_VeADIR_b_LftWEDOpeningFail_Value, sw-syscond=1}
              IN_VeADIR_b_RtWEDClosingFail_Value: accessed-variable=VeADIR_b_RtWEDClosingFail.Value, variation-point={short-label=vpIN_VeADIR_b_RtWEDClosingFail_Value, sw-syscond=1}
              IN_VeADIR_b_RtWEDOpeningFail_Value: accessed-variable=VeADIR_b_RtWEDOpeningFail.Value, variation-point={short-label=vpIN_VeADIR_b_RtWEDOpeningFail_Value, sw-syscond=1}
              IN_VeHSER_e_AWDStatDsrd_Value: accessed-variable=VeHSER_e_AWDStatDsrd.Value, variation-point={short-label=vpIN_VeHSER_e_AWDStatDsrd_Value, sw-syscond=1}
              IN_VeICSR_M_NxCL_Value: accessed-variable=VeICSR_M_NxCL.Value, variation-point={short-label=vpIN_VeICSR_M_NxCL_Value, sw-syscond=1}
              IN_VeMSPR_dn_MtrA_Accel_Value: accessed-variable=VeMSPR_dn_MtrA_Accel.Value, variation-point={short-label=vpIN_VeMSPR_dn_MtrA_Accel_Value, sw-syscond=1}
              IN_VeMSPR_dn_MtrB_Accel_Value: accessed-variable=VeMSPR_dn_MtrB_Accel.Value, variation-point={short-label=vpIN_VeMSPR_dn_MtrB_Accel_Value, sw-syscond=1}
              IN_VeMSPR_dn_MtrC_Accel_Value: accessed-variable=VeMSPR_dn_MtrC_Accel.Value, variation-point={short-label=vpIN_VeMSPR_dn_MtrC_Accel_Value, sw-syscond=1}
              IN_VeMSPR_n_MtrA_Spd_Value: accessed-variable=VeMSPR_n_MtrA_Spd.Value, variation-point={short-label=vpIN_VeMSPR_n_MtrA_Spd_Value, sw-syscond=1}
              IN_VeMSPR_n_MtrB_Spd_Value: accessed-variable=VeMSPR_n_MtrB_Spd.Value, variation-point={short-label=vpIN_VeMSPR_n_MtrB_Spd_Value, sw-syscond=1}
              IN_VeMSPR_n_MtrC_Spd_Value: accessed-variable=VeMSPR_n_MtrC_Spd.Value, variation-point={short-label=vpIN_VeMSPR_n_MtrC_Spd_Value, sw-syscond=1}
              IN_VeMTIR_M_MtrA_TorqAchieved_Value: accessed-variable=VeMTIR_M_MtrA_TorqAchieved.Value, variation-point={short-label=vpIN_VeMTIR_M_MtrA_TorqAchieved_Value, sw-syscond=1}
              IN_VeMTIR_M_MtrB_TorqAchieved_Value: accessed-variable=VeMTIR_M_MtrB_TorqAchieved.Value, variation-point={short-label=vpIN_VeMTIR_M_MtrB_TorqAchieved_Value, sw-syscond=1}
              IN_VeMTIR_M_MtrC_TorqAchieved_Value: accessed-variable=VeMTIR_M_MtrC_TorqAchieved.Value, variation-point={short-label=vpIN_VeMTIR_M_MtrC_TorqAchieved_Value, sw-syscond=1}
              IN_VeRTMR_e_WEDLearningProcedure_Value: accessed-variable=VeRTMR_e_WEDLearningProcedure.Value, variation-point={short-label=vpIN_VeRTMR_e_WEDLearningProcedure_Value, sw-syscond=1}
              IN_VeVSDR_n_WEDLeftWheel_Value: accessed-variable=VeVSDR_n_WEDLeftWheel.Value, variation-point={short-label=vpIN_VeVSDR_n_WEDLeftWheel_Value, sw-syscond=1}
              IN_VeVSDR_n_WEDRightWheel_Value: accessed-variable=VeVSDR_n_WEDRightWheel.Value, variation-point={short-label=vpIN_VeVSDR_n_WEDRightWheel_Value, sw-syscond=1}
          data-send-points:
            13 x access:
              OUT_VeADCR_e_WEDLeftStat_Value: accessed-variable=VeADCR_e_WEDLeftStat.Value
              OUT_VeADCR_e_WEDRightStat_Value: accessed-variable=VeADCR_e_WEDRightStat.Value
              OUT_VeADCR_e_WEDLftCmndStat_Value: accessed-variable=VeADCR_e_WEDLftCmndStat.Value
              OUT_VeADCR_e_WEDRtCmndStat_Value: accessed-variable=VeADCR_e_WEDRtCmndStat.Value
              OUT_VeADCR_M_WEDMtrCLMax_Value: accessed-variable=VeADCR_M_WEDMtrCLMax.Value
              OUT_VeADCR_M_WEDMtrCLMin_Value: accessed-variable=VeADCR_M_WEDMtrCLMin.Value
              OUT_VeADCR_Cnt_RtWEDClsngAttempts_Value: accessed-variable=VeADCR_Cnt_RtWEDClsngAttempts.Value
              OUT_VeADCR_Cnt_RtWEDOpngAttempts_Value: accessed-variable=VeADCR_Cnt_RtWEDOpngAttempts.Value
              OUT_VeADCR_e_WEDLeftCmndMgrSt_Value: accessed-variable=VeADCR_e_WEDLeftCmndMgrSt.Value
              OUT_VeADCR_e_WEDRightCmndMgrSt_Value: accessed-variable=VeADCR_e_WEDRightCmndMgrSt.Value
              OUT_VeADCR_Cnt_LftWEDClsngAttempts_Value: accessed-variable=VeADCR_Cnt_LftWEDClsngAttempts.Value
              OUT_VeADCR_Cnt_LftWEDOpngAttempts_Value: accessed-variable=VeADCR_Cnt_LftWEDOpngAttempts.Value
              OUT_VeADCR_b_WiggleRequest_Value: accessed-variable=VeADCR_b_WiggleRequest.Value
          parameter access CALPRM_HeTSXR_e_NxDomain_HeTSXR_e_NxDomain: accessed-parameter=HeTSXR_e_NxDomain.HeTSXR_e_NxDomain, variation-point={short-label=vpCALPRM_HeTSXR_e_NxDomain_HeTSXR_e_NxDomain, sw-syscond=1}
          parameter access CALPRM_KeTSXR_D_ExternWEDMtrDmpng_KeTSXR_D_ExternWEDMtrDmpng: accessed-parameter=KeTSXR_D_ExternWEDMtrDmpng.KeTSXR_D_ExternWEDMtrDmpng, variation-point={short-label=vpCALPRM_KeTSXR_D_ExternWEDMtrDmpng_KeTSXR_D_ExternWEDMtrDmpng, sw-syscond=1}
          parameter access CALPRM_KeTSXR_J_ExternWEDMtrInertia_KeTSXR_J_ExternWEDMtrInertia: accessed-parameter=KeTSXR_J_ExternWEDMtrInertia.KeTSXR_J_ExternWEDMtrInertia, variation-point={short-label=vpCALPRM_KeTSXR_J_ExternWEDMtrInertia_KeTSXR_J_ExternWEDMtrInertia, sw-syscond=1}
          written-local-variables:
            8 x access:
              WV_VeADCC_b_ClchLocked_IRV: accessed-variable=VeADCC_b_ClchLocked_IRV, variation-point={short-label=vpWV_VeADCC_b_ClchLocked_IRV, sw-syscond=1}
              WV_VeADCC_e_AWDClchXStat_IRV: accessed-variable=VeADCC_e_AWDClchXStat_IRV, variation-point={short-label=vpWV_VeADCC_e_AWDClchXStat_IRV, sw-syscond=1}
              WV_VeADCC_e_AWDClchYStat_IRV: accessed-variable=VeADCC_e_AWDClchYStat_IRV, variation-point={short-label=vpWV_VeADCC_e_AWDClchYStat_IRV, sw-syscond=1}
              WV_VeADCC_m_WEDThruTorq_IRV: accessed-variable=VeADCC_m_WEDThruTorq_IRV, variation-point={short-label=vpWV_VeADCC_m_WEDThruTorq_IRV, sw-syscond=1}
              WV_VeADCR_dn_NxDotAct_IRV: accessed-variable=VeADCR_dn_NxDotAct_IRV, variation-point={short-label=vpWV_VeADCR_dn_NxDotAct_IRV, sw-syscond=1}
              WV_VeADCR_e_AWDClchXRawStat_IRV: accessed-variable=VeADCR_e_AWDClchXRawStat_IRV, variation-point={short-label=vpWV_VeADCR_e_AWDClchXRawStat_IRV, sw-syscond=1}
              WV_VeADCR_e_AWDClchYRawStat_IRV: accessed-variable=VeADCR_e_AWDClchYRawStat_IRV, variation-point={short-label=vpWV_VeADCR_e_AWDClchYRawStat_IRV, sw-syscond=1}
              WV_VeADCR_n_NxAct_IRV: accessed-variable=VeADCR_n_NxAct_IRV, variation-point={short-label=vpWV_VeADCR_n_NxAct_IRV, sw-syscond=1}
        ADCR_MedTED1
          data-receive-point-by-arguments:
            5 x access:
              IN_VeHSER_e_AWDStatDsrd_Value: accessed-variable=VeHSER_e_AWDStatDsrd.Value, variation-point={short-label=vpIN_VeHSER_e_AWDStatDsrd_Value, sw-syscond=1}
              IN_VeHTDR_M_Clch2_TCR_Actl_Value: accessed-variable=VeHTDR_M_Clch2_TCR_Actl.Value, variation-point={short-label=vpIN_VeHTDR_M_Clch2_TCR_Actl_Value, sw-syscond=1}
              IN_VeVSDR_n_PrimNoSgndFltrd_Value: accessed-variable=VeVSDR_n_PrimNoSgndFltrd.Value, variation-point={short-label=vpIN_VeVSDR_n_PrimNoSgndFltrd_Value, sw-syscond=1}
              IN_VeVSDR_n_WEDLeftWheel_Value: accessed-variable=VeVSDR_n_WEDLeftWheel.Value, variation-point={short-label=vpIN_VeVSDR_n_WEDLeftWheel_Value, sw-syscond=1}
              IN_VeVSDR_n_WEDRightWheel_Value: accessed-variable=VeVSDR_n_WEDRightWheel.Value, variation-point={short-label=vpIN_VeVSDR_n_WEDRightWheel_Value, sw-syscond=1}
          data-send-points:
            12 x access:
              OUT_VeADCR_e_WEDAxleStat_Value: accessed-variable=VeADCR_e_WEDAxleStat.Value
              OUT_VeADCR_i_WEDAxleStat_CAN_Value: accessed-variable=VeADCR_i_WEDAxleStat_CAN.Value
              OUT_VeADCR_n_AWDNxTgt_Value: accessed-variable=VeADCR_n_AWDNxTgt.Value
              OUT_VeADCR_dn_AWDNxTgtDot_Value: accessed-variable=VeADCR_dn_AWDNxTgtDot.Value
              OUT_VeADCR_M_AWDClch_TcR_Ovrd_Value: accessed-variable=VeADCR_M_AWDClch_TcR_Ovrd.Value
              OUT_VeADCR_M_AWDClch_LeadTcR_Ovrd_Value: accessed-variable=VeADCR_M_AWDClch_LeadTcR_Ovrd.Value
              OUT_VeADCR_b_AWDUseLckedEqn_Value: accessed-variable=VeADCR_b_AWDUseLckedEqn.Value
              OUT_VeADCR_k_AWDNxProfFilt_Value: accessed-variable=VeADCR_k_AWDNxProfFilt.Value
              OUT_VeADCR_M_AWDClch_TorqEst_Value: accessed-variable=VeADCR_M_AWDClch_TorqEst.Value
              OUT_VeADCR_b_ADCOfldCnfm_Value: accessed-variable=VeADCR_b_ADCOfldCnfm.Value
              OUT_VeADCR_e_AWDSysStat_Value: accessed-variable=VeADCR_e_AWDSysStat.Value
              OUT_VeADCR_e_AWDDiscCurrSt_Value: accessed-variable=VeADCR_e_AWDDiscCurrSt.Value
          read-local-variables:
            8 x access:
              RV_VeADCC_b_ClchLocked_IRV: accessed-variable=VeADCC_b_ClchLocked_IRV, variation-point={short-label=vpRV_VeADCC_b_ClchLocked_IRV, sw-syscond=1}
              RV_VeADCC_e_AWDClchXStat_IRV: accessed-variable=VeADCC_e_AWDClchXStat_IRV, variation-point={short-label=vpRV_VeADCC_e_AWDClchXStat_IRV, sw-syscond=1}
              RV_VeADCC_e_AWDClchYStat_IRV: accessed-variable=VeADCC_e_AWDClchYStat_IRV, variation-point={short-label=vpRV_VeADCC_e_AWDClchYStat_IRV, sw-syscond=1}
              RV_VeADCC_m_WEDThruTorq_IRV: accessed-variable=VeADCC_m_WEDThruTorq_IRV, variation-point={short-label=vpRV_VeADCC_m_WEDThruTorq_IRV, sw-syscond=1}
              RV_VeADCR_dn_NxDotAct_IRV: accessed-variable=VeADCR_dn_NxDotAct_IRV, variation-point={short-label=vpRV_VeADCR_dn_NxDotAct_IRV, sw-syscond=1}
              RV_VeADCR_e_AWDClchXRawStat_IRV: accessed-variable=VeADCR_e_AWDClchXRawStat_IRV, variation-point={short-label=vpRV_VeADCR_e_AWDClchXRawStat_IRV, sw-syscond=1}
              RV_VeADCR_e_AWDClchYRawStat_IRV: accessed-variable=VeADCR_e_AWDClchYRawStat_IRV, variation-point={short-label=vpRV_VeADCR_e_AWDClchYRawStat_IRV, sw-syscond=1}
              RV_VeADCR_n_NxAct_IRV: accessed-variable=VeADCR_n_NxAct_IRV, variation-point={short-label=vpRV_VeADCR_n_NxAct_IRV, sw-syscond=1}
        ADCR_MedTED2
          data-receive-point-by-arguments:
            access IN_VeADIR_e_BSM_WEDModeReq_Value: accessed-variable=VeADIR_e_BSM_WEDModeReq.Value, variation-point={short-label=vpIN_VeADIR_e_BSM_WEDModeReq_Value, sw-syscond=1}
            access IN_VeLLDR_e_AWDDiscnctAllwd_Value: accessed-variable=VeLLDR_e_AWDDiscnctAllwd.Value, variation-point={short-label=vpIN_VeLLDR_e_AWDDiscnctAllwd_Value, sw-syscond=1}
            access IN_VeVSDR_n_PrimNoSgndFltrd_Value: accessed-variable=VeVSDR_n_PrimNoSgndFltrd.Value, variation-point={short-label=vpIN_VeVSDR_n_PrimNoSgndFltrd_Value, sw-syscond=1}
          data-send-points:
            access OUT_VeADCR_e_WEDCmndArb_Value: accessed-variable=VeADCR_e_WEDCmndArb.Value
            access OUT_VeADCR_i_WEDCmndArbPrioLvl_Value: accessed-variable=VeADCR_i_WEDCmndArbPrioLvl.Value
        ADCR_MedTEB2
          data-receive-point-by-arguments:
            13 x access:
              IN_VaTSXR_r_HTDRToConstrn_Value: accessed-variable=VaTSXR_r_HTDRToConstrn.Value, variation-point={short-label=vpIN_VaTSXR_r_HTDRToConstrn_Value, sw-syscond=1}
              IN_VeESMR_P_BattLTMaxLim_Value: accessed-variable=VeESMR_P_BattLTMaxLim.Value, variation-point={short-label=vpIN_VeESMR_P_BattLTMaxLim_Value, sw-syscond=1}
              IN_VeHSER_dn_InputAccelProfile_Value: accessed-variable=VeHSER_dn_InputAccelProfile.Value, variation-point={short-label=vpIN_VeHSER_dn_InputAccelProfile_Value, sw-syscond=1}
              IN_VeHSER_dn_NxDotProfile_Value: accessed-variable=VeHSER_dn_NxDotProfile.Value, variation-point={short-label=vpIN_VeHSER_dn_NxDotProfile_Value, sw-syscond=1}
              IN_VeHSER_n_NxProfSmthDly_Value: accessed-variable=VeHSER_n_NxProfSmthDly.Value, variation-point={short-label=vpIN_VeHSER_n_NxProfSmthDly_Value, sw-syscond=1}
              IN_VeMSPR_n_MtrA_Spd_Value: accessed-variable=VeMSPR_n_MtrA_Spd.Value, variation-point={short-label=vpIN_VeMSPR_n_MtrA_Spd_Value, sw-syscond=1}
              IN_VeMSPR_n_MtrB_Spd_Value: accessed-variable=VeMSPR_n_MtrB_Spd.Value, variation-point={short-label=vpIN_VeMSPR_n_MtrB_Spd_Value, sw-syscond=1}
              IN_VeMSPR_n_MtrC_Spd_Value: accessed-variable=VeMSPR_n_MtrC_Spd.Value, variation-point={short-label=vpIN_VeMSPR_n_MtrC_Spd_Value, sw-syscond=1}
              IN_VeTISR_n_InputSpeed_Value: accessed-variable=VeTISR_n_InputSpeed.Value, variation-point={short-label=vpIN_VeTISR_n_InputSpeed_Value, sw-syscond=1}
              IN_VeTITR_M_TiFinal_Value: accessed-variable=VeTITR_M_TiFinal.Value, variation-point={short-label=vpIN_VeTITR_M_TiFinal_Value, sw-syscond=1}
              IN_VeVSDR_n_PrimNoSgndFltrd_Value: accessed-variable=VeVSDR_n_PrimNoSgndFltrd.Value, variation-point={short-label=vpIN_VeVSDR_n_PrimNoSgndFltrd_Value, sw-syscond=1}
              IN_VeVSDR_n_WEDLeftWheel_Value: accessed-variable=VeVSDR_n_WEDLeftWheel.Value, variation-point={short-label=vpIN_VeVSDR_n_WEDLeftWheel_Value, sw-syscond=1}
              IN_VeVSDR_n_WEDRightWheel_Value: accessed-variable=VeVSDR_n_WEDRightWheel.Value, variation-point={short-label=vpIN_VeVSDR_n_WEDRightWheel_Value, sw-syscond=1}
          data-send-points:
            access OUT_VeADCR_P_PwrRsrv4EngmtRaw_Value: accessed-variable=VeADCR_P_PwrRsrv4EngmtRaw.Value
            access OUT_VeADCR_P_PwrRsrv4Engmt_Value: accessed-variable=VeADCR_P_PwrRsrv4Engmt.Value
            access OUT_VeADCR_P_PwrRsrv4EngmtLead_Value: accessed-variable=VeADCR_P_PwrRsrv4EngmtLead.Value
          15 x parameter access:
            CALPRM_HeTSXR_e_NxDomain_HeTSXR_e_NxDomain: accessed-parameter=HeTSXR_e_NxDomain.HeTSXR_e_NxDomain, variation-point={short-label=vpCALPRM_HeTSXR_e_NxDomain_HeTSXR_e_NxDomain, sw-syscond=1}
            CALPRM_KaHSCR_k_Donut_Space_Coefs_A1_KaHSCR_k_Donut_Space_Coefs_A1: accessed-parameter=KaHSCR_k_Donut_Space_Coefs_A1.KaHSCR_k_Donut_Space_Coefs_A1, variation-point={short-label=vpCALPRM_KaHSCR_k_Donut_Space_Coefs_A1_KaHSCR_k_Donut_Space_Coefs_A1, sw-syscond=1}
            CALPRM_KaHSCR_k_Donut_Space_Coefs_A2_KaHSCR_k_Donut_Space_Coefs_A2: accessed-parameter=KaHSCR_k_Donut_Space_Coefs_A2.KaHSCR_k_Donut_Space_Coefs_A2, variation-point={short-label=vpCALPRM_KaHSCR_k_Donut_Space_Coefs_A2_KaHSCR_k_Donut_Space_Coefs_A2, sw-syscond=1}
            CALPRM_KaHSCR_k_Donut_Space_Coefs_B1_KaHSCR_k_Donut_Space_Coefs_B1: accessed-parameter=KaHSCR_k_Donut_Space_Coefs_B1.KaHSCR_k_Donut_Space_Coefs_B1, variation-point={short-label=vpCALPRM_KaHSCR_k_Donut_Space_Coefs_B1_KaHSCR_k_Donut_Space_Coefs_B1, sw-syscond=1}
            CALPRM_KaHSCR_k_Donut_Space_Coefs_B2_KaHSCR_k_Donut_Space_Coefs_B2: accessed-parameter=KaHSCR_k_Donut_Space_Coefs_B2.KaHSCR_k_Donut_Space_Coefs_B2, variation-point={short-label=vpCALPRM_KaHSCR_k_Donut_Space_Coefs_B2_KaHSCR_k_Donut_Space_Coefs_B2, sw-syscond=1}
            CALPRM_KaHSCR_k_Donut_Space_Coefs_C_KaHSCR_k_Donut_Space_Coefs_C: accessed-parameter=KaHSCR_k_Donut_Space_Coefs_C.KaHSCR_k_Donut_Space_Coefs_C, variation-point={short-label=vpCALPRM_KaHSCR_k_Donut_Space_Coefs_C_KaHSCR_k_Donut_Space_Coefs_C, sw-syscond=1}
            CALPRM_KaHSCR_k_Donut_Space_Coefs_C1_KaHSCR_k_Donut_Space_Coefs_C1: accessed-parameter=KaHSCR_k_Donut_Space_Coefs_C1.KaHSCR_k_Donut_Space_Coefs_C1, variation-point={short-label=vpCALPRM_KaHSCR_k_Donut_Space_Coefs_C1_KaHSCR_k_Donut_Space_Coefs_C1, sw-syscond=1}
            CALPRM_KaHSCR_k_Donut_Space_Coefs_C2_KaHSCR_k_Donut_Space_Coefs_C2: accessed-parameter=KaHSCR_k_Donut_Space_Coefs_C2.KaHSCR_k_Donut_Space_Coefs_C2, variation-point={short-label=vpCALPRM_KaHSCR_k_Donut_Space_Coefs_C2_KaHSCR_k_Donut_Space_Coefs_C2, sw-syscond=1}
            CALPRM_KaHSCR_k_Donut_Space_Coefs_D_KaHSCR_k_Donut_Space_Coefs_D: accessed-parameter=KaHSCR_k_Donut_Space_Coefs_D.KaHSCR_k_Donut_Space_Coefs_D, variation-point={short-label=vpCALPRM_KaHSCR_k_Donut_Space_Coefs_D_KaHSCR_k_Donut_Space_Coefs_D, sw-syscond=1}
            CALPRM_KaHSCR_k_Donut_Space_Coefs_E_KaHSCR_k_Donut_Space_Coefs_E: accessed-parameter=KaHSCR_k_Donut_Space_Coefs_E.KaHSCR_k_Donut_Space_Coefs_E, variation-point={short-label=vpCALPRM_KaHSCR_k_Donut_Space_Coefs_E_KaHSCR_k_Donut_Space_Coefs_E, sw-syscond=1}
            CALPRM_KaHSCR_n_DonutSpaceCoeffs_AxisA_KaHSCR_n_DonutSpaceCoeffs_AxisA: accessed-parameter=KaHSCR_n_DonutSpaceCoeffs_AxisA.KaHSCR_n_DonutSpaceCoeffs_AxisA, variation-point={short-label=vpCALPRM_KaHSCR_n_DonutSpaceCoeffs_AxisA_KaHSCR_n_DonutSpaceCoeffs_AxisA, sw-syscond=1}
            CALPRM_KaHSCR_n_DonutSpaceCoeffs_AxisB_KaHSCR_n_DonutSpaceCoeffs_AxisB: accessed-parameter=KaHSCR_n_DonutSpaceCoeffs_AxisB.KaHSCR_n_DonutSpaceCoeffs_AxisB, variation-point={short-label=vpCALPRM_KaHSCR_n_DonutSpaceCoeffs_AxisB_KaHSCR_n_DonutSpaceCoeffs_AxisB, sw-syscond=1}
            CALPRM_KaHSCR_n_DonutSpaceCoeffs_AxisC_KaHSCR_n_DonutSpaceCoeffs_AxisC: accessed-parameter=KaHSCR_n_DonutSpaceCoeffs_AxisC.KaHSCR_n_DonutSpaceCoeffs_AxisC, variation-point={short-label=vpCALPRM_KaHSCR_n_DonutSpaceCoeffs_AxisC_KaHSCR_n_DonutSpaceCoeffs_AxisC, sw-syscond=1}
            CALPRM_KeTSXR_J_Ia_KeTSXR_J_Ia: accessed-parameter=KeTSXR_J_Ia.KeTSXR_J_Ia, variation-point={short-label=vpCALPRM_KeTSXR_J_Ia_KeTSXR_J_Ia, sw-syscond=1}
            CALPRM_KeTSXR_J_Ib_KeTSXR_J_Ib: accessed-parameter=KeTSXR_J_Ib.KeTSXR_J_Ib, variation-point={short-label=vpCALPRM_KeTSXR_J_Ib_KeTSXR_J_Ib, sw-syscond=1}
      variation point proxy Variant_ADCR_FUNC_TRUE: category=CONDITION, condition-access=1
      variation point proxy Variant_ADCR_NF_TRUE: category=CONDITION, condition-access=0
